AUTOSAR XML (schema 00048)
package /SecurityArchitecture/ComponentTypes
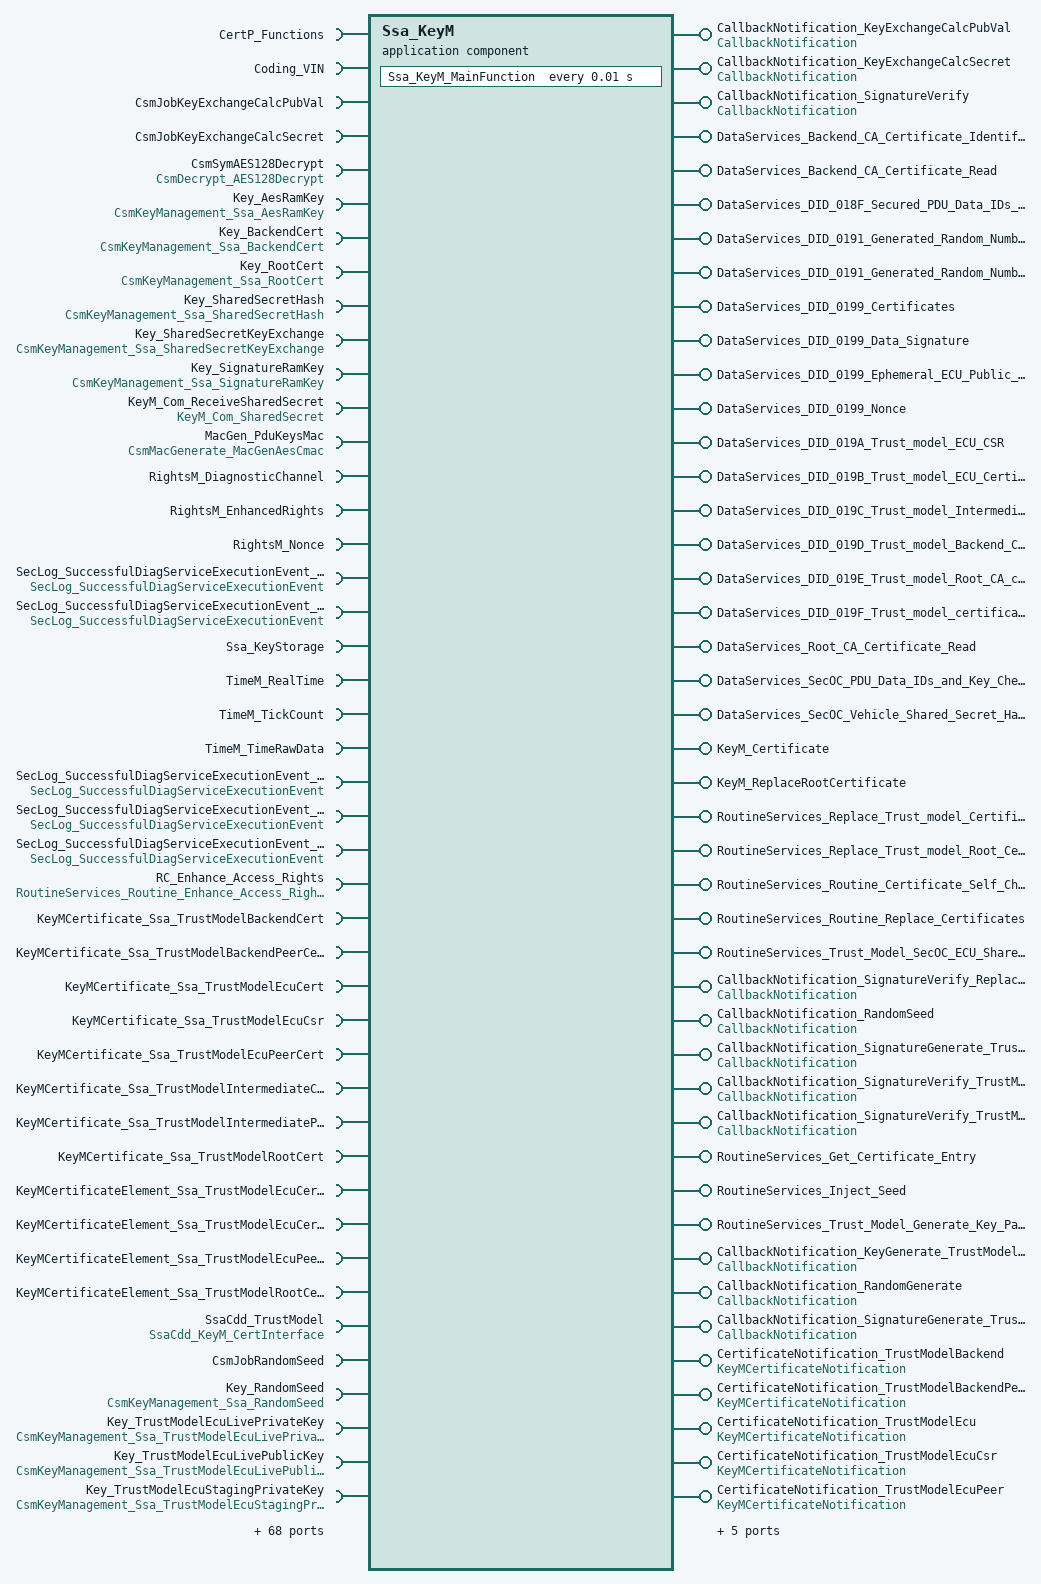
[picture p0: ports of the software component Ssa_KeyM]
  application sw component type Ssa_KeyM
    28 x provide port:
      CallbackNotification_KeyExchangeCalcPubVal: server-com-spec{operation=CallbackNotification, queue-length=1}, provided-interface=CallbackNotification  # Callback notification from the CSM key exchange calculate public value job. Configuration Variant(s): Asynchronous key management job processing.
      CallbackNotification_KeyExchangeCalcSecret: server-com-spec{operation=CallbackNotification, queue-length=1}, provided-interface=CallbackNotification  # Callback notification from the CSM key exchange calculate secret job. Configuration Variant(s): Asynchronous key management job processing.
      CallbackNotification_SignatureVerify: server-com-spec{operation=CallbackNotification, queue-length=1}, provided-interface=CallbackNotification  # Callback notification from the CSM signature verification job used for verifying the signature of passed data with a temporary public key. Configuration Variant(s): Asynchronous job processing.
      DataServices_Backend_CA_Certificate_Identification_Read_Backend_CA_SubjectKeyIdentifier: provided-com-specs=[{operation=ConditionCheckRead, queue-length=1}, {operation=ReadData, queue-length=1}], provided-interface=DataServices_Backend_CA_Certificate_Identification_Read_Backend_CA_SubjectKeyIdentifier  # Reads subject key identifier of backend certificate and pass it to given data parameter. Connect to corresponding Dcm port.
      DataServices_Backend_CA_Certificate_Read: provided-interface=DataServices_Backend_CA_Certificate_Read  # Reads backend certificate and pass it to given data parameter. Connect to corresponding Dcm port.
        provided-com-specs:
          operation=ConditionCheckRead, queue-length=1
          operation=ReadData, queue-length=1
          operation=ReadDataLength, queue-length=1
      DataServices_DID_018F_Secured_PDU_Data_IDs_and_Key_CMACs: provided-interface=DataServices_DID_018F_Secured_PDU_Data_IDs_and_Key_CMACs  # Retrieves all SecOC Data-IDs of the secured PDUs and their corresponding truncated MAC from the ECU.
        provided-com-specs:
          operation=ConditionCheckRead, queue-length=1
          operation=ReadData, queue-length=1
          operation=ReadDataLength, queue-length=1
      DataServices_DID_0191_Generated_Random_Number: provided-com-specs=[{operation=ConditionCheckRead, queue-length=1}, {operation=ReadData, queue-length=1}], provided-interface=DataServices_DID_0191_Generated_Random_Number
      DataServices_DID_0191_Generated_Random_Number_Result: provided-com-specs=[{operation=ConditionCheckRead, queue-length=1}, {operation=ReadData, queue-length=1}], provided-interface=DataServices_DID_0191_Generated_Random_Number_Result
      DataServices_DID_0199_Certificates: provided-interface=DataServices_DID_0199_Certificates  # Reads the certificates and passes it to given data parameter - Unique ECU ID chain. Connect to corresponding Dcm port. Configuration Variant(s): Not in VSM.
        provided-com-specs:
          operation=ConditionCheckRead, queue-length=1
          operation=ReadData, queue-length=1
          operation=ReadDataLength, queue-length=1
      DataServices_DID_0199_Data_Signature: provided-com-specs=[{operation=ConditionCheckRead, queue-length=1}, {operation=ReadData, queue-length=1}], provided-interface=DataServices_DID_0199_Data_Signature  # Reads a signature which was calculated over nonce and ephemeral key and passes it to given data parameter - Unique ECU ID chain. Connect to corresponding Dcm port. Configuration Variant(s): Not in VSM.
      DataServices_DID_0199_Ephemeral_ECU_Public_Key: provided-com-specs=[{operation=ConditionCheckRead, queue-length=1}, {operation=ReadData, queue-length=1}], provided-interface=DataServices_DID_0199_Ephemeral_ECU_Public_Key  # Reads the ephemeral public key and passes it to given data parameter - Unique ECU ID chain. Connect to corresponding Dcm port. Configuration Variant(s): Not in VSM.
      DataServices_DID_0199_Nonce: provided-com-specs=[{operation=ConditionCheckRead, queue-length=1}, {operation=ReadData, queue-length=1}], provided-interface=DataServices_DID_0199_Nonce  # Reads the nonce and passes it to given data parameter - Unique ECU ID chain. Connect to corresponding Dcm port. Configuration Variant(s): Not in VSM.
      DataServices_DID_019A_Trust_model_ECU_CSR: provided-interface=DataServices_DID_019A_Trust_model_ECU_CSR
        provided-com-specs:
          operation=ConditionCheckRead, queue-length=1
          operation=ReadData, queue-length=1
          operation=ReadDataLength, queue-length=1
      DataServices_DID_019B_Trust_model_ECU_Certificate: provided-interface=DataServices_DID_019B_Trust_model_ECU_Certificate
        provided-com-specs:
          operation=ConditionCheckRead, queue-length=1
          operation=ReadData, queue-length=1
          operation=ReadDataLength, queue-length=1
      DataServices_DID_019C_Trust_model_Intermediate_CA_Certificate: provided-interface=DataServices_DID_019C_Trust_model_Intermediate_CA_Certificate
        provided-com-specs:
          operation=ConditionCheckRead, queue-length=1
          operation=ReadData, queue-length=1
          operation=ReadDataLength, queue-length=1
      DataServices_DID_019D_Trust_model_Backend_CA_certificate: provided-interface=DataServices_DID_019D_Trust_model_Backend_CA_certificate
        provided-com-specs:
          operation=ConditionCheckRead, queue-length=1
          operation=ReadData, queue-length=1
          operation=ReadDataLength, queue-length=1
      DataServices_DID_019E_Trust_model_Root_CA_certificate: provided-interface=DataServices_DID_019E_Trust_model_Root_CA_certificate
        provided-com-specs:
          operation=ConditionCheckRead, queue-length=1
          operation=ReadData, queue-length=1
          operation=ReadDataLength, queue-length=1
      DataServices_DID_019F_Trust_model_certificates: provided-interface=DataServices_DID_019F_Trust_model_certificates
        provided-com-specs:
          operation=ConditionCheckRead, queue-length=1
          operation=ReadData, queue-length=1
          operation=ReadDataLength, queue-length=1
      DataServices_Root_CA_Certificate_Read: provided-interface=DataServices_Root_CA_Certificate_Read  # Reads root certificate and passes it to given data parameter. Connect to corresponding Dcm port.
        provided-com-specs:
          operation=ConditionCheckRead, queue-length=1
          operation=ReadData, queue-length=1
          operation=ReadDataLength, queue-length=1
      DataServices_SecOC_PDU_Data_IDs_and_Key_Checksum_Read_Secured_PDU_Data_IDs_and_Key_Checksum: provided-interface=DataServices_SecOC_PDU_Data_IDs_and_Key_Checksum_Read_Secured_PDU_Data_IDs_and_Key_Checksum  # Reads checksum of pdu data identifiers and passes it to given data parameter. Connect to corresponding Dcm port.
        provided-com-specs:
          operation=ConditionCheckRead, queue-length=1
          operation=ReadData, queue-length=1
          operation=ReadDataLength, queue-length=1
      DataServices_SecOC_Vehicle_Shared_Secret_Hash_Read_SecOC_Vehicle_Shared_Secret_Hash: provided-com-specs=[{operation=ConditionCheckRead, queue-length=1}, {operation=ReadData, queue-length=1}], provided-interface=DataServices_SecOC_Vehicle_Shared_Secret_Hash_Read_SecOC_Vehicle_Shared_Secret_Hash  # Reads hash value of shared secret and passes it to given data parameter. Connect to corresponding Dcm port.
      KeyM_Certificate: provided-interface=KeyM_Certificate
        provided-com-specs:
          operation=GetBackendSerialNumber, queue-length=1
          operation=GetBackendSubject, queue-length=1
          operation=VerifyCertWithBackendCert, queue-length=1
          operation=SignData4092ByteWithEcuPrivateKey, queue-length=1
          operation=VerifyCertWithBackendCert, queue-length=1
          operation=SignData1024ByteWithEcuPrivateKey, queue-length=1
          operation=CheckTrustModelChainOfTrust, queue-length=1
      KeyM_ReplaceRootCertificate: nonqueued-sender-com-spec{data-element=isProductive, init-value=constant-reference=Ssa_Init_boolean_False}, provided-interface=KeyM_ReplaceRootCertificate
      RoutineServices_Replace_Trust_model_Certificates: server-com-spec{operation=Start, queue-length=1}, provided-interface=RoutineServices_Replace_Trust_model_Certificates
      RoutineServices_Replace_Trust_model_Root_Certificate: server-com-spec{operation=Start, queue-length=1}, provided-interface=RoutineServices_Replace_Trust_model_Root_Certificate
      RoutineServices_Routine_Certificate_Self_Check: server-com-spec{operation=Start, queue-length=1}, provided-interface=RoutineServices_Routine_Certificate_Self_Check  # Verifies the chain of trust of the stored certificates and their compatibility to the private key.
      RoutineServices_Routine_Replace_Certificates: server-com-spec{operation=Start, queue-length=1}, provided-interface=RoutineServices_Routine_Replace_Certificates  # Replaces the currently stored ECU Certificate, Backend CA Certificate or Root CA Certificate. The Root CA Certificate may only be replaced together with the Backend CA Certificate. The Backend CA Certificate may only be exchanged together with the ECU Certificate. Replacement of Root or Backend certificate needs a corresponding link certificate.
      RoutineServices_Trust_Model_SecOC_ECU_Shared_Secret_Distribution: server-com-spec{operation=Start, queue-length=1}, provided-interface=RoutineServices_Trust_Model_SecOC_ECU_Shared_Secret_Distribution  # Start the distribution of the shared secret - Unique ECU ID chain. Configuration Variant(s): Not in VSM.
    25 x require port:
      CertP_Functions: required-interface=CertP_Functions
        required-com-specs:
          AttributeCertificate_Parse
          Certificate_Compare
          Certificate_Parse
          Certificate_Verify
          Certificate_Verify_Extended
          ParseTime
      Coding_VIN: client-com-spec=Get, required-interface=Coding_VIN
      CsmJobKeyExchangeCalcPubVal: required-com-specs=[CancelJob, KeyExchangeCalcPubVal], required-interface=CsmJobKeyExchangeCalcPubVal  # Calculates a key exchange public value. Connect to a Csm KeyExchangeCalcPubVal job. Configuration Variant(s): Asynchronous key management job processing.
      CsmJobKeyExchangeCalcSecret: required-com-specs=[CancelJob, KeyExchangeCalcSecret], required-interface=CsmJobKeyExchangeCalcSecret  # Calculates a key exchange secret. Connect to a Csm KeyExchangeCalcSecret job. Configuration Variant(s): Asynchronous key management job processing.
      CsmSymAES128Decrypt: client-com-spec=Decrypt, required-interface=CsmDecrypt_AES128Decrypt  # Decrypt data using AES128 with formerly set AesRamKey. Connect to a Csm Decrypt Job which uses the RAM key set through port Key_AesRamKey. Configuration Variant(s): Not in VSM.
      Key_AesRamKey: required-com-specs=[KeyElementGet, KeyElementSet, KeySetValid], required-interface=CsmKeyManagement_Ssa_AesRamKey  # Sets the key used for en- or decrypting the nonce and shared secret. Connect to a Csm Key which is able to store a symmetric key and is used in AES jobs.
      Key_BackendCert: required-com-specs=[KeyElementGet, KeyElementSet, KeySetValid], required-interface=CsmKeyManagement_Ssa_BackendCert  # Key is used to store the Backend certificate. Connect to a Csm Key which is able to store raw certificate data.
      Key_RootCert: required-com-specs=[KeyElementGet, KeyElementSet, KeySetValid], required-interface=CsmKeyManagement_Ssa_RootCert  # Key is used to store the Root certificate. Connect to a Csm Key which is able to store raw certificate data.
      Key_SharedSecretHash: required-com-specs=[KeyElementGet, KeyElementSet, KeySetValid], required-interface=CsmKeyManagement_Ssa_SharedSecretHash  # Key is used to store the proof of the shared secret. Connect to a Csm Key which is able to store a proof of a key.
      Key_SharedSecretKeyExchange: required-com-specs=[KeyElementGet, KeyElementSet, KeyExchangeCalcPubVal, KeyExchangeCalcSecret, KeySetValid], required-interface=CsmKeyManagement_Ssa_SharedSecretKeyExchange  # Key is used to generate a common key between two ecu based on the exchange of its public keys. Connect to a Csm Key which is able to calculate a common secret.
      Key_SignatureRamKey: required-com-specs=[KeyElementGet, KeyElementSet, KeySetValid], required-interface=CsmKeyManagement_Ssa_SignatureRamKey  # Sets the public key of a certificate to verify data signed by this certificate. Connect to a Csm Key which is able to store a public key and is used in job of port CsmSignatureVerify.
      KeyM_Com_ReceiveSharedSecret: nonqueued-receiver-com-spec{data-element=sharedSecret, filter=data-filter-type=ALWAYS, init-value=constant-reference=Ssa_Init_Zero_32Byte}, required-interface=KeyM_Com_SharedSecret  # Configuration Variant(s): Not in VSM.
      MacGen_PduKeysMac: client-com-spec=MacGenerate, required-interface=CsmMacGenerate_MacGenAesCmac  # Generates the MAC from PDU data ID and constant. Connect to a Csm Mac Generate Job which uses the PDU keys MAC key for ReadDataByIdentifier service 0x018F.
      RightsM_DiagnosticChannel: required-com-specs=[GetDiagChanAndAuthStatus, GetDiagnosticUserRole, GetDiagnosticUserRolesBitMask, GetPostProductionStatus], required-interface=RightsM_DiagnosticChannel
      RightsM_EnhancedRights: client-com-spec=VerifySubjectKeyIdentifier, required-interface=RightsM_EnhancedRights
      RightsM_Nonce: required-com-specs=[Destroy, Get], required-interface=RightsM_Nonce
      SecLog_SuccessfulDiagServiceExecutionEvent_EcuSharedSecretDistribution: client-com-spec=SuccessfulDiagServiceExecution, required-interface=SecLog_SuccessfulDiagServiceExecutionEvent  # Configuration Variant(s): Not in VSM.
      SecLog_SuccessfulDiagServiceExecutionEvent_ReplaceCert: client-com-spec=SuccessfulDiagServiceExecution, required-interface=SecLog_SuccessfulDiagServiceExecutionEvent
      Ssa_KeyStorage: client-com-spec=StorePermanently, required-interface=Ssa_KeyStorage
      TimeM_RealTime: required-com-specs=[Compare, Get, Set], required-interface=TimeM_RealTime
      TimeM_TickCount: client-com-spec=Get, required-interface=TimeM_TickCount
      TimeM_TimeRawData: required-com-specs=[Get, Set, ResetLocalTickCount], required-interface=TimeM_TimeRawData
      SecLog_SuccessfulDiagServiceExecutionEvent_ReplaceTrustModelCert: client-com-spec=SuccessfulDiagServiceExecution, required-interface=SecLog_SuccessfulDiagServiceExecutionEvent
      SecLog_SuccessfulDiagServiceExecutionEvent_ReplaceTrustModeRootCert: client-com-spec=SuccessfulDiagServiceExecution, required-interface=SecLog_SuccessfulDiagServiceExecutionEvent
      SecLog_SuccessfulDiagServiceExecutionEvent_TrustModelEcuSharedSecretDistribution: client-com-spec=SuccessfulDiagServiceExecution, required-interface=SecLog_SuccessfulDiagServiceExecutionEvent  # Configuration Variant(s): Not in VSM.
    provide port CallbackNotification_SignatureVerify_ReplacementAuthority: server-com-spec{operation=CallbackNotification, queue-length=1}, provided-interface=CallbackNotification  # Callback notification from the CSM signature verification job used for verifying the signature of passed data with the replacement authority public key. Configuration Variant(s): Asynchronous job processing.
    14 x require port:
      RC_Enhance_Access_Rights: client-com-spec=Start, required-interface=RoutineServices_Routine_Enhance_Access_Rights
      KeyMCertificate_Ssa_TrustModelBackendCert: required-com-specs=[GetStatus, VerifyCertificate], required-interface=KeyMCertificate_Ssa_TrustModelBackendCert
      KeyMCertificate_Ssa_TrustModelBackendPeerCert: required-com-specs=[GetStatus, VerifyCertificate], required-interface=KeyMCertificate_Ssa_TrustModelBackendPeerCert
      KeyMCertificate_Ssa_TrustModelEcuCert: required-com-specs=[GetStatus, VerifyCertificate], required-interface=KeyMCertificate_Ssa_TrustModelEcuCert
      KeyMCertificate_Ssa_TrustModelEcuCsr: required-com-specs=[GetStatus, VerifyCertificate], required-interface=KeyMCertificate_Ssa_TrustModelEcuCsr
      KeyMCertificate_Ssa_TrustModelEcuPeerCert: required-com-specs=[GetStatus, VerifyCertificate], required-interface=KeyMCertificate_Ssa_TrustModelEcuPeerCert
      KeyMCertificate_Ssa_TrustModelIntermediateCert: required-com-specs=[GetStatus, VerifyCertificate], required-interface=KeyMCertificate_Ssa_TrustModelIntermediateCert
      KeyMCertificate_Ssa_TrustModelIntermediatePeerCert: required-com-specs=[GetStatus, VerifyCertificate], required-interface=KeyMCertificate_Ssa_TrustModelIntermediatePeerCert
      KeyMCertificate_Ssa_TrustModelRootCert: required-com-specs=[GetStatus, VerifyCertificate], required-interface=KeyMCertificate_Ssa_TrustModelRootCert
      KeyMCertificateElement_Ssa_TrustModelEcuCert_ext_subKeyId: client-com-spec=CertificateElementGet, required-interface=KeyMCertificateElement_Ssa_TrustModelEcuCert_ext_subKeyId
      KeyMCertificateElement_Ssa_TrustModelEcuCert_ext_uniqueECUID: client-com-spec=CertificateElementGet, required-interface=KeyMCertificateElement_Ssa_TrustModelEcuCert_ext_uniqueECUID
      KeyMCertificateElement_Ssa_TrustModelEcuPeerCert_ext_subKeyId: client-com-spec=CertificateElementGet, required-interface=KeyMCertificateElement_Ssa_TrustModelEcuPeerCert_ext_subKeyId
      KeyMCertificateElement_Ssa_TrustModelRootCert_ext_subKeyId: client-com-spec=CertificateElementGet, required-interface=KeyMCertificateElement_Ssa_TrustModelRootCert_ext_subKeyId
      SsaCdd_TrustModel: required-com-specs=[CsrElementSet, GetCertificate, ServiceCertificate, SetCertificate], required-interface=SsaCdd_KeyM_CertInterface
    7 x provide port:
      CallbackNotification_RandomSeed: server-com-spec{operation=CallbackNotification, queue-length=1}, provided-interface=CallbackNotification  # Callback notification from the CSM random seed job. Configuration Variant(s): Asynchronous key management job processing. Configuration Variant(s): Not in VSM.
      CallbackNotification_SignatureGenerate_TrustModelEcuLive: server-com-spec{operation=CallbackNotification, queue-length=1}, provided-interface=CallbackNotification  # Callback notification from the CSM signature generation job used for generating signatures with the Trust Model ECU live key. Configuration Variant(s): Asynchronous job processing.
      CallbackNotification_SignatureVerify_TrustModelBackend: server-com-spec{operation=CallbackNotification, queue-length=1}, provided-interface=CallbackNotification  # Callback notification from the CSM signature verification job used for verifying the signature of passed data with the public key of the Trust Model Backend CA certificate. Configuration Variant(s): Asynchronous job processing. Configuration Variant(s): Not in VSM.
      CallbackNotification_SignatureVerify_TrustModelTemp: server-com-spec{operation=CallbackNotification, queue-length=1}, provided-interface=CallbackNotification  # Callback notification from the CSM signature verification job used for verifying the signature of passed data with a Trust Model temporary public key. Configuration Variant(s): Asynchronous job processing.
      RoutineServices_Get_Certificate_Entry: server-com-spec{operation=Start, queue-length=1}, provided-interface=RoutineServices_Get_Certificate_Entry  # Routine to read out a specific certificate entry of one of the stored certificates. Connect to DCM.
      RoutineServices_Inject_Seed: server-com-spec{operation=Start, queue-length=1}, provided-interface=RoutineServices_Inject_Seed  # Configuration Variant(s): Not in VSM.
      RoutineServices_Trust_Model_Generate_Key_Pair: server-com-spec{operation=Start, queue-length=1}, provided-interface=RoutineServices_Trust_Model_Generate_Key_Pair
    31 x require port:
      CsmJobRandomSeed: required-com-specs=[CancelJob, RandomSeed], required-interface=CsmJobRandomSeed  # Seeding the random generation algorithm. Connect to a Csm RandomSeed job. Configuration Variant(s): Asynchronous key management job processing. Configuration Variant(s): Not in VSM.
      Key_RandomSeed: required-com-specs=[KeySetValid, RandomSeed], required-interface=CsmKeyManagement_Ssa_RandomSeed  # Key is used to store the seed which shall be used as input for a pseudo random generator. Connect to a Csm Key which is able to store a seed and used by random generator
      Key_TrustModelEcuLivePrivateKey: required-com-specs=[KeyCopy, KeyElementCopy, KeyElementGet, KeyElementSet, KeySetValid], required-interface=CsmKeyManagement_Ssa_TrustModelEcuLivePrivateKey  # Connect to Csm key that is used as private key for the Trust Model ECU certificate.
      Key_TrustModelEcuLivePublicKey: required-com-specs=[KeyCopy, KeyElementCopy, KeyElementGet, KeyElementSet, KeySetValid], required-interface=CsmKeyManagement_Ssa_TrustModelEcuLivePublicKey  # Connect to Csm key that is used as public key for the Trust Model ECU certificate.
      Key_TrustModelEcuStagingPrivateKey: required-com-specs=[KeyCopy, KeyElementCopy, KeyElementGet, KeyElementSet, KeySetValid], required-interface=CsmKeyManagement_Ssa_TrustModelEcuStagingPrivateKey  # Connect to Csm key that is used as private key for the Trust Model ECU CSR certificate.
      Key_TrustModelEcuStagingPublicKey: required-com-specs=[KeyCopy, KeyElementCopy, KeyElementGet, KeyElementSet, KeySetValid], required-interface=CsmKeyManagement_Ssa_TrustModelEcuStagingPublicKey  # Connect to Csm key that is used as public key for the Trust Model ECU CSR certificate.
      Key_TrustModelTempPublicKey: required-com-specs=[KeyCopy, KeyElementCopy, KeyElementGet, KeyElementSet, KeySetValid], required-interface=CsmKeyManagement_Ssa_TrustModelTempPublicKey  # Connect to Csm key that is used as public key for the Trust Model ECU peer certificate.
      KeyMCertificateElement_Ssa_TrustModelBackendCert_ext_authKeyId: client-com-spec=CertificateElementGet, required-interface=KeyMCertificateElement_Ssa_TrustModelBackendCert_ext_authKeyId
      KeyMCertificateElement_Ssa_TrustModelBackendCert_ext_subKeyId: client-com-spec=CertificateElementGet, required-interface=KeyMCertificateElement_Ssa_TrustModelBackendCert_ext_subKeyId
      KeyMCertificateElement_Ssa_TrustModelBackendCert_Issuer: client-com-spec=CertificateElementGet, required-interface=KeyMCertificateElement_Ssa_TrustModelBackendCert_Issuer
      KeyMCertificateElement_Ssa_TrustModelBackendCert_SerialNo: client-com-spec=CertificateElementGet, required-interface=KeyMCertificateElement_Ssa_TrustModelBackendCert_SerialNo
      KeyMCertificateElement_Ssa_TrustModelBackendCert_subject: client-com-spec=CertificateElementGet, required-interface=KeyMCertificateElement_Ssa_TrustModelBackendCert_subject
      KeyMCertificateElement_Ssa_TrustModelBackendCert_SubjectPublicKeyInfoKey: client-com-spec=CertificateElementGet, required-interface=KeyMCertificateElement_Ssa_TrustModelBackendCert_SubjectPublicKeyInfoKey
      KeyMCertificateElement_Ssa_TrustModelEcuCert_ext_authKeyId: client-com-spec=CertificateElementGet, required-interface=KeyMCertificateElement_Ssa_TrustModelEcuCert_ext_authKeyId
      KeyMCertificateElement_Ssa_TrustModelEcuCert_ext_specialEcu: client-com-spec=CertificateElementGet, required-interface=KeyMCertificateElement_Ssa_TrustModelEcuCert_ext_specialEcu
      KeyMCertificateElement_Ssa_TrustModelEcuCert_Issuer: client-com-spec=CertificateElementGet, required-interface=KeyMCertificateElement_Ssa_TrustModelEcuCert_Issuer
      KeyMCertificateElement_Ssa_TrustModelEcuCert_SerialNo: client-com-spec=CertificateElementGet, required-interface=KeyMCertificateElement_Ssa_TrustModelEcuCert_SerialNo
      KeyMCertificateElement_Ssa_TrustModelEcuCert_subject: client-com-spec=CertificateElementGet, required-interface=KeyMCertificateElement_Ssa_TrustModelEcuCert_subject
      KeyMCertificateElement_Ssa_TrustModelEcuCert_SubjectPublicKeyInfoKey: client-com-spec=CertificateElementGet, required-interface=KeyMCertificateElement_Ssa_TrustModelEcuCert_SubjectPublicKeyInfoKey
      KeyMCertificateElement_Ssa_TrustModelIntermediateCert_ext_authKeyId: client-com-spec=CertificateElementGet, required-interface=KeyMCertificateElement_Ssa_TrustModelIntermediateCert_ext_authKeyId
      KeyMCertificateElement_Ssa_TrustModelIntermediateCert_ext_subKeyId: client-com-spec=CertificateElementGet, required-interface=KeyMCertificateElement_Ssa_TrustModelIntermediateCert_ext_subKeyId
      KeyMCertificateElement_Ssa_TrustModelIntermediateCert_Issuer: client-com-spec=CertificateElementGet, required-interface=KeyMCertificateElement_Ssa_TrustModelIntermediateCert_Issuer
      KeyMCertificateElement_Ssa_TrustModelIntermediateCert_SerialNo: client-com-spec=CertificateElementGet, required-interface=KeyMCertificateElement_Ssa_TrustModelIntermediateCert_SerialNo
      KeyMCertificateElement_Ssa_TrustModelIntermediateCert_subject: client-com-spec=CertificateElementGet, required-interface=KeyMCertificateElement_Ssa_TrustModelIntermediateCert_subject
      KeyMCertificateElement_Ssa_TrustModelIntermediateCert_SubjectPublicKeyInfoKey: client-com-spec=CertificateElementGet, required-interface=KeyMCertificateElement_Ssa_TrustModelIntermediateCert_SubjectPublicKeyInfoKey
      KeyMCertificateElement_Ssa_TrustModelRootCert_ext_keyUsage: client-com-spec=CertificateElementGet, required-interface=KeyMCertificateElement_Ssa_TrustModelRootCert_ext_keyUsage
      KeyMCertificateElement_Ssa_TrustModelRootCert_Issuer: client-com-spec=CertificateElementGet, required-interface=KeyMCertificateElement_Ssa_TrustModelRootCert_Issuer
      KeyMCertificateElement_Ssa_TrustModelRootCert_SerialNo: client-com-spec=CertificateElementGet, required-interface=KeyMCertificateElement_Ssa_TrustModelRootCert_SerialNo
      KeyMCertificateElement_Ssa_TrustModelRootCert_subject: client-com-spec=CertificateElementGet, required-interface=KeyMCertificateElement_Ssa_TrustModelRootCert_subject
      KeyMCertificateElement_Ssa_TrustModelRootCert_SubjectPublicKeyInfoKey: client-com-spec=CertificateElementGet, required-interface=KeyMCertificateElement_Ssa_TrustModelRootCert_SubjectPublicKeyInfoKey
      Ssa_KeyProc: required-com-specs=[GenerateKeyPair, PrepareKeyExchange], required-interface=Ssa_KeyProc
    13 x provide port:
      CallbackNotification_KeyGenerate_TrustModelEcuCsr: server-com-spec{operation=CallbackNotification, queue-length=1}, provided-interface=CallbackNotification  # Callback notification from the CSM key generate job. Configuration Variant(s): Asynchronous key management job processing.
      CallbackNotification_RandomGenerate: server-com-spec{operation=CallbackNotification, queue-length=1}, provided-interface=CallbackNotification  # Callback notification from the CSM random generate job. Configuration Variant(s): Asynchronous job processing.
      CallbackNotification_SignatureGenerate_TrustModelEcuCsr: server-com-spec{operation=CallbackNotification, queue-length=1}, provided-interface=CallbackNotification  # Callback notification from the CSM signature generation job used for generating signatures with the Trust Model ECU CSR key. Configuration Variant(s): Asynchronous job processing.
      CertificateNotification_TrustModelBackend: provided-interface=KeyMCertificateNotification
        provided-com-specs:
          operation=CertificateVerifyCallbackNotification, queue-length=1
          operation=ServiceCertificateCallbackNotification, queue-length=1
      CertificateNotification_TrustModelBackendPeer: provided-interface=KeyMCertificateNotification
        provided-com-specs:
          operation=CertificateVerifyCallbackNotification, queue-length=1
          operation=ServiceCertificateCallbackNotification, queue-length=1
      CertificateNotification_TrustModelEcu: provided-interface=KeyMCertificateNotification
        provided-com-specs:
          operation=CertificateVerifyCallbackNotification, queue-length=1
          operation=ServiceCertificateCallbackNotification, queue-length=1
      CertificateNotification_TrustModelEcuCsr: provided-interface=KeyMCertificateNotification
        provided-com-specs:
          operation=CertificateVerifyCallbackNotification, queue-length=1
          operation=ServiceCertificateCallbackNotification, queue-length=1
      CertificateNotification_TrustModelEcuPeer: provided-interface=KeyMCertificateNotification
        provided-com-specs:
          operation=CertificateVerifyCallbackNotification, queue-length=1
          operation=ServiceCertificateCallbackNotification, queue-length=1
      CertificateNotification_TrustModelIntermediate: provided-interface=KeyMCertificateNotification
        provided-com-specs:
          operation=CertificateVerifyCallbackNotification, queue-length=1
          operation=ServiceCertificateCallbackNotification, queue-length=1
      CertificateNotification_TrustModelIntermediatePeer: provided-interface=KeyMCertificateNotification
        provided-com-specs:
          operation=CertificateVerifyCallbackNotification, queue-length=1
          operation=ServiceCertificateCallbackNotification, queue-length=1
      CertificateNotification_TrustModelRoot: provided-interface=KeyMCertificateNotification
        provided-com-specs:
          operation=CertificateVerifyCallbackNotification, queue-length=1
          operation=ServiceCertificateCallbackNotification, queue-length=1
      DataServices_DID_0198_Root_Replacement_Key: provided-com-specs=[{operation=ConditionCheckRead, queue-length=1}, {operation=ReadData, queue-length=1}], provided-interface=DataServices_DID_0198_Root_Replacement_Key  # Reads the Trust Model Root Replacement Key and passes it to the given data parameter. Connect to corresponding Dcm port.
      Ssa_MacKeyGeneration_State: mode-switch-sender-com-spec{mode-group=State, queue-length=1}, provided-interface=Ssa_MacKeyGeneration_State
    42 x require port:
      CsmJobKeyGenerate_TrustModelEcuCsr: required-com-specs=[CancelJob, KeyGenerate], required-interface=CsmJobKeyGenerate  # Generates a new unique ECU key pair. Connect to a Csm KeyGenerate job of the Ed25519 algorithm family. Configuration Variant(s): Asynchronous key management job processing.
      CsmRandomGenerate: client-com-spec=RandomGenerate, required-interface=CsmRandomGenerate_Random  # Generates a random number. Connect to a Csm Random job.
      CsmSymAES128DecryptWithPadding: client-com-spec=Decrypt, required-interface=CsmDecrypt_AES128DecryptWithPadding  # Decrypt data using AES128 with formerly set AesRamKey. Padding bytes needs to be considered. Connect to a Csm Decrypt Job which uses the RAM key set through port Key_AesRamKey. Configuration Variant(s): Not in VSM.
      Key_TrustModelEcuCsrPrivateKey: required-com-specs=[KeyCopy, KeyElementCopy, KeyElementGet, KeyElementSet, KeyGenerate, KeySetValid], required-interface=CsmKeyManagement_Ssa_TrustModelEcuCsrPrivateKey
      Key_TrustModelEcuCsrPublicKey: required-com-specs=[KeyCopy, KeyElementCopy, KeyElementGet, KeyElementSet, KeySetValid], required-interface=CsmKeyManagement_Ssa_TrustModelEcuCsrPublicKey
      Key_TrustModelRootReplacementKey: required-com-specs=[KeyCopy, KeyElementCopy, KeyElementGet, KeyElementSet, KeySetValid], required-interface=CsmKeyManagement_Ssa_SigPubKey_ReplacementAuthority  # Connect to Csm key that is used for signature verification over the New Root CA Certificate package.
      KeyMCertificateElement_Ssa_TrustModelBackendCert_ext_basicConstraints: client-com-spec=CertificateElementGet, required-interface=KeyMCertificateElement_Ssa_TrustModelBackendCert_ext_basicConstraints
      KeyMCertificateElement_Ssa_TrustModelBackendCert_validityNotAfter: client-com-spec=CertificateElementGet, required-interface=KeyMCertificateElement_Ssa_TrustModelBackendCert_validityNotAfter
      KeyMCertificateElement_Ssa_TrustModelBackendCert_Version: client-com-spec=CertificateElementGet, required-interface=KeyMCertificateElement_Ssa_TrustModelBackendCert_Version
      KeyMCertificateElement_Ssa_TrustModelBackendPeerCert_ext_authKeyId: client-com-spec=CertificateElementGet, required-interface=KeyMCertificateElement_Ssa_TrustModelBackendPeerCert_ext_authKeyId
      KeyMCertificateElement_Ssa_TrustModelBackendPeerCert_ext_basicConstraints: client-com-spec=CertificateElementGet, required-interface=KeyMCertificateElement_Ssa_TrustModelBackendPeerCert_ext_basicConstraints
      KeyMCertificateElement_Ssa_TrustModelBackendPeerCert_ext_subKeyId: client-com-spec=CertificateElementGet, required-interface=KeyMCertificateElement_Ssa_TrustModelBackendPeerCert_ext_subKeyId
      KeyMCertificateElement_Ssa_TrustModelBackendPeerCert_SerialNo: client-com-spec=CertificateElementGet, required-interface=KeyMCertificateElement_Ssa_TrustModelBackendPeerCert_SerialNo
      KeyMCertificateElement_Ssa_TrustModelBackendPeerCert_validityNotAfter: client-com-spec=CertificateElementGet, required-interface=KeyMCertificateElement_Ssa_TrustModelBackendPeerCert_validityNotAfter
      KeyMCertificateElement_Ssa_TrustModelBackendPeerCert_Version: client-com-spec=CertificateElementGet, required-interface=KeyMCertificateElement_Ssa_TrustModelBackendPeerCert_Version
      KeyMCertificateElement_Ssa_TrustModelEcuCert_validityNotAfter: client-com-spec=CertificateElementGet, required-interface=KeyMCertificateElement_Ssa_TrustModelEcuCert_validityNotAfter
      KeyMCertificateElement_Ssa_TrustModelEcuCert_Version: client-com-spec=CertificateElementGet, required-interface=KeyMCertificateElement_Ssa_TrustModelEcuCert_Version
      KeyMCertificateElement_Ssa_TrustModelEcuPeerCert_ext_authKeyId: client-com-spec=CertificateElementGet, required-interface=KeyMCertificateElement_Ssa_TrustModelEcuPeerCert_ext_authKeyId
      KeyMCertificateElement_Ssa_TrustModelEcuPeerCert_ext_specialEcu: client-com-spec=CertificateElementGet, required-interface=KeyMCertificateElement_Ssa_TrustModelEcuPeerCert_ext_specialEcu
      KeyMCertificateElement_Ssa_TrustModelEcuPeerCert_SerialNo: client-com-spec=CertificateElementGet, required-interface=KeyMCertificateElement_Ssa_TrustModelEcuPeerCert_SerialNo
      KeyMCertificateElement_Ssa_TrustModelEcuPeerCert_validityNotAfter: client-com-spec=CertificateElementGet, required-interface=KeyMCertificateElement_Ssa_TrustModelEcuPeerCert_validityNotAfter
      KeyMCertificateElement_Ssa_TrustModelEcuPeerCert_Version: client-com-spec=CertificateElementGet, required-interface=KeyMCertificateElement_Ssa_TrustModelEcuPeerCert_Version
      KeyMCertificateElement_Ssa_TrustModelIntermediateCert_ext_basicConstraints: client-com-spec=CertificateElementGet, required-interface=KeyMCertificateElement_Ssa_TrustModelIntermediateCert_ext_basicConstraints
      KeyMCertificateElement_Ssa_TrustModelIntermediateCert_validityNotAfter: client-com-spec=CertificateElementGet, required-interface=KeyMCertificateElement_Ssa_TrustModelIntermediateCert_validityNotAfter
      KeyMCertificateElement_Ssa_TrustModelIntermediateCert_Version: client-com-spec=CertificateElementGet, required-interface=KeyMCertificateElement_Ssa_TrustModelIntermediateCert_Version
      KeyMCertificateElement_Ssa_TrustModelIntermediatePeerCert_ext_authKeyId: client-com-spec=CertificateElementGet, required-interface=KeyMCertificateElement_Ssa_TrustModelIntermediatePeerCert_ext_authKeyId
      KeyMCertificateElement_Ssa_TrustModelIntermediatePeerCert_ext_basicConstraints: client-com-spec=CertificateElementGet, required-interface=KeyMCertificateElement_Ssa_TrustModelIntermediatePeerCert_ext_basicConstraints
      KeyMCertificateElement_Ssa_TrustModelIntermediatePeerCert_ext_subKeyId: client-com-spec=CertificateElementGet, required-interface=KeyMCertificateElement_Ssa_TrustModelIntermediatePeerCert_ext_subKeyId
      KeyMCertificateElement_Ssa_TrustModelIntermediatePeerCert_SerialNo: client-com-spec=CertificateElementGet, required-interface=KeyMCertificateElement_Ssa_TrustModelIntermediatePeerCert_SerialNo
      KeyMCertificateElement_Ssa_TrustModelIntermediatePeerCert_validityNotAfter: client-com-spec=CertificateElementGet, required-interface=KeyMCertificateElement_Ssa_TrustModelIntermediatePeerCert_validityNotAfter
      KeyMCertificateElement_Ssa_TrustModelIntermediatePeerCert_Version: client-com-spec=CertificateElementGet, required-interface=KeyMCertificateElement_Ssa_TrustModelIntermediatePeerCert_Version
      KeyMCertificateElement_Ssa_TrustModelRootCert_ext_basicConstraints: client-com-spec=CertificateElementGet, required-interface=KeyMCertificateElement_Ssa_TrustModelRootCert_ext_basicConstraints
      KeyMCertificateElement_Ssa_TrustModelRootCert_validityNotAfter: client-com-spec=CertificateElementGet, required-interface=KeyMCertificateElement_Ssa_TrustModelRootCert_validityNotAfter
      KeyMCertificateElement_Ssa_TrustModelRootCert_Version: client-com-spec=CertificateElementGet, required-interface=KeyMCertificateElement_Ssa_TrustModelRootCert_Version
      NvMService_KeyM_TrustModelChainOfTrustState: required-com-specs=[GetErrorStatus, ReadBlock, SetRamBlockStatus, WriteBlock], required-interface=NvMService_AC2_SRBS
      SecLog_FailedCertVerificationEvent: client-com-spec=FailedCertificateVerification, required-interface=SecLog_FailedCertVerificationEvent
      SecLog_SuccessfulCertVerificationEvent: client-com-spec=SuccessfulCertificateVerification, required-interface=SecLog_SuccessfulCertVerificationEvent
      SecLog_SuccessfulDiagServiceExecutionEvent_InjectSeed: client-com-spec=SuccessfulDiagServiceExecution, required-interface=SecLog_SuccessfulDiagServiceExecutionEvent  # Configuration Variant(s): Not in VSM.
      SecLog_SuccessfulDiagServiceExecutionEvent_TrustModelGenerateKeyPair: client-com-spec=SuccessfulDiagServiceExecution, required-interface=SecLog_SuccessfulDiagServiceExecutionEvent
      Ssa_VeDocRelevantInfo: client-com-spec=GetData, required-interface=Ssa_VeDocRelevantInfo  # Requests for the VeDoc relevant information, e.g., to be used as common name in the Trust Model CSR.
      SsaCdd_Csm: required-com-specs=[CancelJob, Hash, SignatureGenerate, SignatureVerify], required-interface=SsaCdd_CryptoInterface
      SsaCdd_Keys: required-com-specs=[KeyElementCopy, KeyElementGet, KeyElementSet, KeySetValid], required-interface=SsaCdd_Csm_KeyInterface
    behavior Ssa_KeyM_InternalBehavior: data-type-mapping=SSATypeMappingSet, included-data-type-set=data-type=Ssa_KeyElementType
      exclusive area KeyM_ExclusiveArea
      ar-typed-per-instance-memorys:
        data KeyMTrustModelChainOfTrustState: type=Ssa_TrustModelChainState_Type
      operation invoked event OIT_KeyM_Certificate_GetBackendSerialNumber_KeyM_Certificate_GetBackendSerialNumber: start-on-event=Ssa_KeyM_Certificate_GetBackendSerialNumber, operation=KeyM_Certificate.GetBackendSerialNumber
      operation invoked event OIT_KeyM_KeyM_Certificate_GetBackendSubject_KeyM_Certificate_GetBackendSubject: start-on-event=Ssa_KeyM_Certificate_GetBackendSubject, operation=KeyM_Certificate.GetBackendSubject
      operation invoked event OIT_KeyM_Certificate_VerifyCertWithBackendCert_KeyM_Certificate_VerifyCertWithBackendCert: start-on-event=Ssa_KeyM_Certificate_VerifyCertWithBackendCert, operation=KeyM_Certificate.VerifyCertWithBackendCert
      data received event DRT_KeyM_Com_VehicleSharedSecretNotification_KeyM_ReceiveSharedSecret_sharedSecret: start-on-event=Ssa_KeyM_Com_VehicleSharedSecretNotification, data=KeyM_Com_ReceiveSharedSecret.sharedSecret
      50 x operation invoked event:
        OIT_CallbackNotification_KeyExchangeCalcPubVal_CallbackNotification_CallbackNotification_KeyExchangeCalcPubVal_CallbackND0A1F256: start-on-event=Ssa_KeyM_CsmCallbackNotification_KeyExchangeCalcPubVal, operation=CallbackNotification_KeyExchangeCalcPubVal.CallbackNotification
        OIT_CallbackNotification_KeyExchangeCalcSecret_CallbackNotification_CallbackNotification_KeyExchangeCalcSecret_CallbackN4A055969: start-on-event=Ssa_KeyM_CsmCallbackNotification_KeyExchangeCalcSecret, operation=CallbackNotification_KeyExchangeCalcSecret.CallbackNotification
        OIT_CallbackNotification_SignatureVerify_CallbackNotification_CallbackNotification_SignatureVerify_CallbackNotification: start-on-event=Ssa_KeyM_CsmCallbackNotification_SignatureVerify, operation=CallbackNotification_SignatureVerify.CallbackNotification
        OIT_KeyM_DataServices_Backend_CA_Certificate_Read_ConditionCheckRead_DataServices_Backend_CA_Certificate_Read_ConditionCheckRead: start-on-event=Ssa_KeyM_DataServices_Backend_CA_Certificate_ConditionCheckRead, operation=DataServices_Backend_CA_Certificate_Read.ConditionCheckRead
        OIT_KeyM_DataServices_Backend_CA_Certificate_Identification_Read_Backend_CA_SubjectKeyIdentifier_ConditionCheckRead_Data623BAD1A: start-on-event=Ssa_KeyM_DataServices_Backend_CA_Certificate_Identification_SubjectKeyIdentifier_ConditionCheckRead, operation=DataServices_Backend_CA_Certificate_Identification_Read_Backend_CA_SubjectKeyIdentifier.ConditionCheckRead
        OIT_KeyM_DataServices_Backend_CA_Certificate_Identification_Read_Backend_CA_SubjectKeyIdentifier_ReadData_DataServices_BC7F49EB3: start-on-event=Ssa_KeyM_DataServices_Backend_CA_Certificate_Identification_SubjectKeyIdentifier_ReadData, operation=DataServices_Backend_CA_Certificate_Identification_Read_Backend_CA_SubjectKeyIdentifier.ReadData
        OIT_KeyM_DataServices_Backend_CA_Certificate_Read_ReadData_DataServices_Backend_CA_Certificate_Read_ReadData: start-on-event=Ssa_KeyM_DataServices_Backend_CA_Certificate_ReadData, operation=DataServices_Backend_CA_Certificate_Read.ReadData
        OIT_KeyM_DataServices_Backend_CA_Certificate_Read_ReadDataLength_DataServices_Backend_CA_Certificate_Read_ReadDataLength: start-on-event=Ssa_KeyM_DataServices_Backend_CA_Certificate_ReadDataLength, operation=DataServices_Backend_CA_Certificate_Read.ReadDataLength
        OIT_DataServices_DID_018F_Secured_PDU_Data_IDs_and_Key_CMACs_ConditionCheckRead_DataServices_DID_018F_Secured_PDU_Data_I27C6627C: start-on-event=Ssa_KeyM_DataServices_DID_018F_Secured_PDU_Data_IDs_and_Key_CMACs_ConditionCheckRead, operation=DataServices_DID_018F_Secured_PDU_Data_IDs_and_Key_CMACs.ConditionCheckRead
        OIT_DataServices_DID_018F_Secured_PDU_Data_IDs_and_Key_CMACs_ReadData_DataServices_DID_018F_Secured_PDU_Data_IDs_and_KeyE83D493D: start-on-event=Ssa_KeyM_DataServices_DID_018F_Secured_PDU_Data_IDs_and_Key_CMACs_ReadData, operation=DataServices_DID_018F_Secured_PDU_Data_IDs_and_Key_CMACs.ReadData
        OIT_DataServices_DID_018F_Secured_PDU_Data_IDs_and_Key_CMACs_ReadDataLength_DataServices_DID_018F_Secured_PDU_Data_IDs_a8E9E53EA: start-on-event=Ssa_KeyM_DataServices_DID_018F_Secured_PDU_Data_IDs_and_Key_CMACs_ReadDataLength, operation=DataServices_DID_018F_Secured_PDU_Data_IDs_and_Key_CMACs.ReadDataLength
        OIT_DataServices_DID_0191_Generated_Random_Number_ConditionCheckRead_DataServices_DID_0191_Generated_Random_Number_Condi2EB48B44: start-on-event=Ssa_KeyM_DataServices_DID_0191_Generated_Random_Number_ConditionCheckRead, operation=DataServices_DID_0191_Generated_Random_Number.ConditionCheckRead
        OIT_DataServices_DID_0191_Generated_Random_Number_ReadData_DataServices_DID_0191_Generated_Random_Number_ReadData: start-on-event=Ssa_KeyM_DataServices_DID_0191_Generated_Random_Number_ReadData, operation=DataServices_DID_0191_Generated_Random_Number.ReadData
        OIT_DataServices_DID_0191_Generated_Random_Number_Result_ConditionCheckRead_DataServices_DID_0191_Generated_Random_NumbeC23B856B: start-on-event=Ssa_KeyM_DataServices_DID_0191_Generated_Random_Number_Result_ConditionCheckRead, operation=DataServices_DID_0191_Generated_Random_Number_Result.ConditionCheckRead
        OIT_DataServices_DID_0191_Generated_Random_Number_Result_ReadData_DataServices_DID_0191_Generated_Random_Number_Result_ReadData: start-on-event=Ssa_KeyM_DataServices_DID_0191_Generated_Random_Number_Result_ReadData, operation=DataServices_DID_0191_Generated_Random_Number_Result.ReadData
        OIT_DataServices_DID_0199_Certificates_ConditionCheckRead_DataServices_DID_0199_Certificates_ConditionCheckRead: start-on-event=Ssa_KeyM_DataServices_DID_0199_Certificates_ConditionCheckRead, operation=DataServices_DID_0199_Certificates.ConditionCheckRead
        OIT_DataServices_DID_0199_Certificates_ReadData_DataServices_DID_0199_Certificates_ReadData: start-on-event=Ssa_KeyM_DataServices_DID_0199_Certificates_ReadData, operation=DataServices_DID_0199_Certificates.ReadData
        OIT_DataServices_DID_0199_Certificates_ReadDataLength_DataServices_DID_0199_Certificates_ReadDataLength: start-on-event=Ssa_KeyM_DataServices_DID_0199_Certificates_ReadDataLength, operation=DataServices_DID_0199_Certificates.ReadDataLength
        OIT_DataServices_DID_0199_Data_Signature_ConditionCheckRead_DataServices_DID_0199_Data_Signature_ConditionCheckRead: start-on-event=Ssa_KeyM_DataServices_DID_0199_Data_Signature_ConditionCheckRead, operation=DataServices_DID_0199_Data_Signature.ConditionCheckRead
        OIT_DataServices_DID_0199_Data_Signature_ReadData_DataServices_DID_0199_Data_Signature_ReadData: start-on-event=Ssa_KeyM_DataServices_DID_0199_Data_Signature_ReadData, operation=DataServices_DID_0199_Data_Signature.ReadData
        OIT_DataServices_DID_0199_Ephemeral_ECU_Public_Key_ConditionCheckRead_DataServices_DID_0199_Ephemeral_ECU_Public_Key_ConE39A7F07: start-on-event=Ssa_KeyM_DataServices_DID_0199_Ephemeral_ECU_Public_Key_ConditionCheckRead, operation=DataServices_DID_0199_Ephemeral_ECU_Public_Key.ConditionCheckRead
        OIT_DataServices_DID_0199_Ephemeral_ECU_Public_Key_ReadData_DataServices_DID_0199_Ephemeral_ECU_Public_Key_ReadData: start-on-event=Ssa_KeyM_DataServices_DID_0199_Ephemeral_ECU_Public_Key_ReadData, operation=DataServices_DID_0199_Ephemeral_ECU_Public_Key.ReadData
        OIT_DataServices_DID_0199_Nonce_ConditionCheckRead_DataServices_DID_0199_Nonce_ConditionCheckRead: start-on-event=Ssa_KeyM_DataServices_DID_0199_Nonce_ConditionCheckRead, operation=DataServices_DID_0199_Nonce.ConditionCheckRead
        OIT_DataServices_DID_0199_Nonce_ReadData_DataServices_DID_0199_Nonce_ReadData: start-on-event=Ssa_KeyM_DataServices_DID_0199_Nonce_ReadData, operation=DataServices_DID_0199_Nonce.ReadData
        OIT_DataServices_DID_019A_Trust_model_ECU_CSR_ConditionCheckRead_DataServices_DID_019A_Trust_model_ECU_CSR_ConditionCheckRead: start-on-event=Ssa_KeyM_DataServices_DID_019A_Trust_model_ECU_CSR_ConditionCheckRead, operation=DataServices_DID_019A_Trust_model_ECU_CSR.ConditionCheckRead
        OIT_DataServices_DID_019A_Trust_model_ECU_CSR_ReadData_DataServices_DID_019A_Trust_model_ECU_CSR_ReadData: start-on-event=Ssa_KeyM_DataServices_DID_019A_Trust_model_ECU_CSR_ReadData, operation=DataServices_DID_019A_Trust_model_ECU_CSR.ReadData
        OIT_DataServices_DID_019A_Trust_model_ECU_CSR_ReadDataLength_DataServices_DID_019A_Trust_model_ECU_CSR_ReadDataLength: start-on-event=Ssa_KeyM_DataServices_DID_019A_Trust_model_ECU_CSR_ReadDataLength, operation=DataServices_DID_019A_Trust_model_ECU_CSR.ReadDataLength
        OIT_DataServices_DID_019B_Trust_model_ECU_Certificate_ConditionCheckRead_DataServices_DID_019B_Trust_model_ECU_CertificaDFBBBD9E: start-on-event=Ssa_KeyM_DataServices_DID_019B_Trust_model_ECU_Certificate_ConditionCheckRead, operation=DataServices_DID_019B_Trust_model_ECU_Certificate.ConditionCheckRead
        OIT_DataServices_DID_019B_Trust_model_ECU_Certificate_ReadData_DataServices_DID_019B_Trust_model_ECU_Certificate_ReadData: start-on-event=Ssa_KeyM_DataServices_DID_019B_Trust_model_ECU_Certificate_ReadData, operation=DataServices_DID_019B_Trust_model_ECU_Certificate.ReadData
        OIT_DataServices_DID_019B_Trust_model_ECU_Certificate_ReadDataLength_DataServices_DID_019B_Trust_model_ECU_Certificate_R676F5AD8: start-on-event=Ssa_KeyM_DataServices_DID_019B_Trust_model_ECU_Certificate_ReadDataLength, operation=DataServices_DID_019B_Trust_model_ECU_Certificate.ReadDataLength
        OIT_DataServices_DID_019C_Trust_model_Intermediate_CA_Certificate_ConditionCheckRead_DataServices_DID_019C_Trust_model_IDB6B5447: start-on-event=Ssa_KeyM_DataServices_DID_019C_Trust_model_Intermediate_CA_Certificate_ConditionCheckRead, operation=DataServices_DID_019C_Trust_model_Intermediate_CA_Certificate.ConditionCheckRead
        OIT_DataServices_DID_019C_Trust_model_Intermediate_CA_Certificate_ReadData_DataServices_DID_019C_Trust_model_Intermediat2058FD86: start-on-event=Ssa_KeyM_DataServices_DID_019C_Trust_model_Intermediate_CA_Certificate_ReadData, operation=DataServices_DID_019C_Trust_model_Intermediate_CA_Certificate.ReadData
        OIT_DataServices_DID_019C_Trust_model_Intermediate_CA_Certificate_ReadDataLength_DataServices_DID_019C_Trust_model_Inter10FE0B28: start-on-event=Ssa_KeyM_DataServices_DID_019C_Trust_model_Intermediate_CA_Certificate_ReadDataLength, operation=DataServices_DID_019C_Trust_model_Intermediate_CA_Certificate.ReadDataLength
        OIT_DataServices_DID_019D_Trust_model_Backend_CA_certificate_ConditionCheckRead_DataServices_DID_019D_Trust_model_Backen7B166547: start-on-event=Ssa_KeyM_DataServices_DID_019D_Trust_model_Backend_CA_certificate_ConditionCheckRead, operation=DataServices_DID_019D_Trust_model_Backend_CA_certificate.ConditionCheckRead
        OIT_DataServices_DID_019D_Trust_model_Backend_CA_certificate_ReadData_DataServices_DID_019D_Trust_model_Backend_CA_certi43B2D5AF: start-on-event=Ssa_KeyM_DataServices_DID_019D_Trust_model_Backend_CA_certificate_ReadData, operation=DataServices_DID_019D_Trust_model_Backend_CA_certificate.ReadData
        OIT_DataServices_DID_019D_Trust_model_Backend_CA_certificate_ReadDataLength_DataServices_DID_019D_Trust_model_Backend_CAAB6950B7: start-on-event=Ssa_KeyM_DataServices_DID_019D_Trust_model_Backend_CA_certificate_ReadDataLength, operation=DataServices_DID_019D_Trust_model_Backend_CA_certificate.ReadDataLength
        OIT_DataServices_DID_019E_Trust_model_Root_CA_certificate_ConditionCheckRead_DataServices_DID_019E_Trust_model_Root_CA_cFCCC2278: start-on-event=Ssa_KeyM_DataServices_DID_019E_Trust_model_Root_CA_certificate_ConditionCheckRead, operation=DataServices_DID_019E_Trust_model_Root_CA_certificate.ConditionCheckRead
        OIT_DataServices_DID_019E_Trust_model_Root_CA_certificate_ReadData_DataServices_DID_019E_Trust_model_Root_CA_certificateF1D8D89F: start-on-event=Ssa_KeyM_DataServices_DID_019E_Trust_model_Root_CA_certificate_ReadData, operation=DataServices_DID_019E_Trust_model_Root_CA_certificate.ReadData
        OIT_DataServices_DID_019E_Trust_model_Root_CA_certificate_ReadDataLength_DataServices_DID_019E_Trust_model_Root_CA_certi37DDA313: start-on-event=Ssa_KeyM_DataServices_DID_019E_Trust_model_Root_CA_certificate_ReadDataLength, operation=DataServices_DID_019E_Trust_model_Root_CA_certificate.ReadDataLength
        OIT_DataServices_DID_019F_Trust_model_certificates_ConditionCheckRead_DataServices_DID_019F_Trust_model_certificates_ConC9F0041D: start-on-event=Ssa_KeyM_DataServices_DID_019F_Trust_model_certificates_ConditionCheckRead, operation=DataServices_DID_019F_Trust_model_certificates.ConditionCheckRead
        OIT_DataServices_DID_019F_Trust_model_certificates_ReadData_DataServices_DID_019F_Trust_model_certificates_ReadData: start-on-event=Ssa_KeyM_DataServices_DID_019F_Trust_model_certificates_ReadData, operation=DataServices_DID_019F_Trust_model_certificates.ReadData
        OIT_DataServices_DID_019F_Trust_model_certificates_ReadDataLength_DataServices_DID_019F_Trust_model_certificates_ReadDataLength: start-on-event=Ssa_KeyM_DataServices_DID_019F_Trust_model_certificates_ReadDataLength, operation=DataServices_DID_019F_Trust_model_certificates.ReadDataLength
        OIT_KeyM_DataServices_Root_CA_Certificate_Read_ConditionCheckRead_DataServices_Root_CA_Certificate_Read_ConditionCheckRead: start-on-event=Ssa_KeyM_DataServices_Root_CA_Certificate_Read_ConditionCheckRead, operation=DataServices_Root_CA_Certificate_Read.ConditionCheckRead
        OIT_KeyM_DataServices_Root_CA_Certificate_Read_ReadData_DataServices_Root_CA_Certificate_Read_ReadData: start-on-event=Ssa_KeyM_DataServices_Root_CA_Certificate_Read_ReadData, operation=DataServices_Root_CA_Certificate_Read.ReadData
        OIT_KeyM_DataServices_Root_CA_Certificate_Read_ReadDataLength_DataServices_Root_CA_Certificate_Read_ReadDataLength: start-on-event=Ssa_KeyM_DataServices_Root_CA_Certificate_Read_ReadDataLength, operation=DataServices_Root_CA_Certificate_Read.ReadDataLength
        OIT_DataServices_SecOC_PDU_Data_IDs_and_Key_Checksum_Read_Secured_PDU_Data_IDs_and_Key_Checksum_ConditionCheckRead_DataSFB2915E2: start-on-event=Ssa_KeyM_DataServices_SecOC_PDU_Data_IDs_and_Key_Checksum_ConditionCheckRead, operation=DataServices_SecOC_PDU_Data_IDs_and_Key_Checksum_Read_Secured_PDU_Data_IDs_and_Key_Checksum.ConditionCheckRead
        OIT_DataServices_SecOC_PDU_Data_IDs_and_Key_Checksum_Read_Secured_PDU_Data_IDs_and_Key_Checksum_ReadData_DataServices_Se4D67E2A9: start-on-event=Ssa_KeyM_DataServices_SecOC_PDU_Data_IDs_and_Key_Checksum_ReadData, operation=DataServices_SecOC_PDU_Data_IDs_and_Key_Checksum_Read_Secured_PDU_Data_IDs_and_Key_Checksum.ReadData
        OIT_DataServices_SecOC_PDU_Data_IDs_and_Key_Checksum_Read_Secured_PDU_Data_IDs_and_Key_Checksum_ReadDataLength_DataServi40B113F6: start-on-event=Ssa_KeyM_DataServices_SecOC_PDU_Data_IDs_and_Key_Checksum_ReadDataLength, operation=DataServices_SecOC_PDU_Data_IDs_and_Key_Checksum_Read_Secured_PDU_Data_IDs_and_Key_Checksum.ReadDataLength
        OIT_KeyM_DataServices_SecOC_Vehicle_Shared_Secret_Hash_Read_SecOC_Vehicle_Shared_Secret_Hash_ConditionCheckRead_DataServCCF14E5E: start-on-event=Ssa_KeyM_DataServices_SecOC_Vehicle_Shared_Secret_Hash_ConditionCheckRead, operation=DataServices_SecOC_Vehicle_Shared_Secret_Hash_Read_SecOC_Vehicle_Shared_Secret_Hash.ConditionCheckRead
        OIT_KeyM_DataServices_SecOC_Vehicle_Shared_Secret_Hash_Read_SecOC_Vehicle_Shared_Secret_Hash_ReadData_DataServices_SecOCA8E7B5FF: start-on-event=Ssa_KeyM_DataServices_SecOC_Vehicle_Shared_Secret_Hash_ReadData, operation=DataServices_SecOC_Vehicle_Shared_Secret_Hash_Read_SecOC_Vehicle_Shared_Secret_Hash.ReadData
      init event KeyM_InitEvent: start-on-event=Ssa_KeyM_Init
      timing event TMT_Ssa_KeyM_MainFunction: start-on-event=Ssa_KeyM_MainFunction, period=0.01
      37 x operation invoked event:
        OIT_Ssa_KeyM_RoutineServices_Replace_Certificates_RoutineServices_Routine_Replace_Certificates_Start: start-on-event=Ssa_KeyM_RoutineServices_Replace_Certificates, operation=RoutineServices_Routine_Replace_Certificates.Start
        OIT_RoutineServices_Replace_Trust_model_Certificates_Start_RoutineServices_Replace_Trust_model_Certificates_Start: start-on-event=Ssa_KeyM_RoutineServices_Replace_Trust_model_Certificates, operation=RoutineServices_Replace_Trust_model_Certificates.Start
        OIT_RoutineServices_Replace_Trust_model_Root_Certificate_Start_RoutineServices_Replace_Trust_model_Root_Certificate_Start: start-on-event=Ssa_KeyM_RoutineServices_Replace_Trust_model_Root_Certificate, operation=RoutineServices_Replace_Trust_model_Root_Certificate.Start
        OIT_RoutineServices_Routine_Certificate_Self_Check_Start_RoutineServices_Routine_Certificate_Self_Check_Start: start-on-event=Ssa_KeyM_RoutineServices_Routine_Certificate_Self_Check, operation=RoutineServices_Routine_Certificate_Self_Check.Start
        OIT_RoutineServices_Trust_Model_SecOC_ECU_Shared_Secret_Distribution_Start_RoutineServices_Trust_Model_SecOC_ECU_Shared_36988395: start-on-event=Ssa_KeyM_RoutineServices_Trust_Model_SecOC_ECU_Shared_Secret_Distribution, operation=RoutineServices_Trust_Model_SecOC_ECU_Shared_Secret_Distribution.Start
        OIT_CallbackNotification_RandomGenerateSecret_CallbackNotification_CallbackNotification_RandomGenerateSecret_CallbackNot5A9072CA: start-on-event=Ssa_KeyM_CsmCallbackNotification_RandomGenerate, operation=CallbackNotification_RandomGenerate.CallbackNotification
        OIT_CallbackNotification_SignatureVerify_ReplacementAuthority_CallbackNotification_CallbackNotification_SignatureVerify_73614E2B: start-on-event=Ssa_KeyM_CsmCallbackNotification_SignatureVerify_ReplacementAuthority, operation=CallbackNotification_SignatureVerify_ReplacementAuthority.CallbackNotification
        OIT_Ssa_KeyM_CallbackNotification_KeyGenerate_UniqueEcuKey_CallbackNotification_CallbackNotification_KeyGenerate_UniqueE85276B94: start-on-event=Ssa_KeyM_CsmCallbackNotification_KeyGenerate_TrustModelEcuCsr, operation=CallbackNotification_KeyGenerate_TrustModelEcuCsr.CallbackNotification
        OIT_Ssa_KeyM_CallbackNotification_RandomSeed_CallbackNotification_CallbackNotification_RandomSeed_CallbackNotification: start-on-event=Ssa_KeyM_CsmCallbackNotification_RandomSeed, operation=CallbackNotification_RandomSeed.CallbackNotification
        OIT_CallbackNotification_SignatureVerify_TrustModelBackend_CallbackNotification_CallbackNotification_SignatureVerify_Tru71A027BA: start-on-event=Ssa_KeyM_CsmCallbackNotification_SignatureVerify_TrustModelBackend, operation=CallbackNotification_SignatureVerify_TrustModelBackend.CallbackNotification
        OIT_Ssa_KeyM_RoutineServices_Get_Certificate_Entry_Start_RoutineServices_Get_Certificate_Entry_Start: start-on-event=Ssa_KeyM_RoutineServices_Get_Certificate_Entry_Start, operation=RoutineServices_Get_Certificate_Entry.Start
        OIT_Ssa_KeyM_RoutineServices_Inject_Seed_Start_RoutineServices_Inject_Seed_Start: start-on-event=Ssa_KeyM_RoutineServices_Inject_Seed, operation=RoutineServices_Inject_Seed.Start
        OIT_Ssa_KeyM_RoutineServices_Trust_Model_Generate_Key_Pair_Start_RoutineServices_Trust_Model_Generate_Key_Pair_Start: start-on-event=Ssa_KeyM_RoutineServices_Trust_Model_Generate_Key_Pair, operation=RoutineServices_Trust_Model_Generate_Key_Pair.Start
        OIT_CallbackNotification_SignatureGenerate_TrustModel_CallbackNotification_CallbackNotification_SignatureGenerate_TrustM6E1208F8: start-on-event=Ssa_KeyM_CsmCallbackNotification_SignatureGenerate_TrustModelEcuLive, operation=CallbackNotification_SignatureGenerate_TrustModelEcuLive.CallbackNotification
        OIT_CallbackNotification_SignatureVerify_TrustModel_CallbackNotification_CallbackNotification_SignatureVerify_TrustModelB798FCAA: start-on-event=Ssa_KeyM_CsmCallbackNotification_SignatureVerify_TrustModelTemp, operation=CallbackNotification_SignatureVerify_TrustModelTemp.CallbackNotification
        OIT_KeyM_Certificate_CheckTrustModelChainOfTrust_KeyM_Certificate_CheckTrustModelChainOfTrust: start-on-event=Ssa_KeyM_Certificate_CheckTrustModelChainOfTrust, operation=KeyM_Certificate.CheckTrustModelChainOfTrust
        OIT_KeyM_Certificate_SignData1024ByteWithEcuPrivateKey_KeyM_Certificate_SignData1024ByteWithEcuPrivateKey: start-on-event=Ssa_KeyM_Certificate_SignData1024ByteWithEcuPrivateKey, operation=KeyM_Certificate.SignData1024ByteWithEcuPrivateKey
        OIT_KeyM_Certificate_SignData4092ByteWithEcuPrivateKey_KeyM_Certificate_SignData4092ByteWithEcuPrivateKey: start-on-event=Ssa_KeyM_Certificate_SignData4092ByteWithEcuPrivateKey, operation=KeyM_Certificate.SignData4092ByteWithEcuPrivateKey
        OIT_CallbackNotification_SignatureGenerate_TrustModel_Initial_CallbackNotification_CallbackNotification_SignatureGeneratBD765D2D: start-on-event=Ssa_KeyM_CsmCallbackNotification_SignatureGenerate_TrustModelEcuCsr, operation=CallbackNotification_SignatureGenerate_TrustModelEcuCsr.CallbackNotification
        OIT_DataServices_DID_0198_Root_Replacement_Key_ConditionCheckRead_DataServices_DID_0198_Root_Replacement_Key_ConditionCheckRead: start-on-event=Ssa_KeyM_DataServices_DID_0198_Root_Replacement_Key_ConditionCheckRead, operation=DataServices_DID_0198_Root_Replacement_Key.ConditionCheckRead
        OIT_DataServices_DID_0198_Root_Replacement_Key_ReadData_DataServices_DID_0198_Root_Replacement_Key_ReadData: start-on-event=Ssa_KeyM_DataServices_DID_0198_Root_Replacement_Key_ReadData, operation=DataServices_DID_0198_Root_Replacement_Key.ReadData
        OIT_CertificateNotification_TrustModelBackendCa_CertificateVerifyCallbackNotification_CertificateNotification_TrustModelFDD7CFBA: start-on-event=Ssa_KeyM_KeyMCertificateVerifyCallback_TrustModelBackend, operation=CertificateNotification_TrustModelBackend.CertificateVerifyCallbackNotification
        OIT_CertificateNotification_TrustModelBackendCaPeer_CertificateVerifyCallbackNotification_CertificateNotification_TrustMB16EF89C: start-on-event=Ssa_KeyM_KeyMCertificateVerifyCallback_TrustModelBackendPeer, operation=CertificateNotification_TrustModelBackendPeer.CertificateVerifyCallbackNotification
        OIT_CertificateNotification_TrustModelEcu_CertificateVerifyCallbackNotification_CertificateNotification_TrustModelEcu_CeC72909B7: start-on-event=Ssa_KeyM_KeyMCertificateVerifyCallback_TrustModelEcu, operation=CertificateNotification_TrustModelEcu.CertificateVerifyCallbackNotification
        OIT_CertificateNotification_TrustModelEcuCsr_CertificateVerifyCallbackNotification_CertificateNotification_TrustModelEcuA312EC30: start-on-event=Ssa_KeyM_KeyMCertificateVerifyCallback_TrustModelEcuCsr, operation=CertificateNotification_TrustModelEcuCsr.CertificateVerifyCallbackNotification
        OIT_CertificateNotification_TrustModelEcuPeer_CertificateVerifyCallbackNotification_CertificateNotification_TrustModelEc5F62CAB7: start-on-event=Ssa_KeyM_KeyMCertificateVerifyCallback_TrustModelEcuPeer, operation=CertificateNotification_TrustModelEcuPeer.CertificateVerifyCallbackNotification
        OIT_CertificateNotification_TrustModelIntermediateCa_CertificateVerifyCallbackNotification_CertificateNotification_Trust994774CF: start-on-event=Ssa_KeyM_KeyMCertificateVerifyCallback_TrustModelIntermediate, operation=CertificateNotification_TrustModelIntermediate.CertificateVerifyCallbackNotification
        OIT_CertificateNotification_TrustModelIntermediateCaPeer_CertificateVerifyCallbackNotification_CertificateNotification_T6B37B649: start-on-event=Ssa_KeyM_KeyMCertificateVerifyCallback_TrustModelIntermediatePeer, operation=CertificateNotification_TrustModelIntermediatePeer.CertificateVerifyCallbackNotification
        OIT_CertificateNotification_TrustModelRootCa_CertificateVerifyCallbackNotification_CertificateNotification_TrustModelRoo4D498D67: start-on-event=Ssa_KeyM_KeyMCertificateVerifyCallback_TrustModelRoot, operation=CertificateNotification_TrustModelRoot.CertificateVerifyCallbackNotification
        OIT_CertificateNotification_TrustModelBackendCa_ServiceCertificateCallbackNotification_CertificateNotification_TrustModeF5DE6BA1: start-on-event=Ssa_KeyM_KeyMServiceCertificateCallback_TrustModelBackend, operation=CertificateNotification_TrustModelBackend.ServiceCertificateCallbackNotification
        OIT_CertificateNotification_TrustModelBackendCaPeer_ServiceCertificateCallbackNotification_CertificateNotification_TrustA0BF3411: start-on-event=Ssa_KeyM_KeyMServiceCertificateCallback_TrustModelBackendPeer, operation=CertificateNotification_TrustModelBackendPeer.ServiceCertificateCallbackNotification
        OIT_CertificateNotification_TrustModelEcu_ServiceCertificateCallbackNotification_CertificateNotification_TrustModelEcu_SF95A2917: start-on-event=Ssa_KeyM_KeyMServiceCertificateCallback_TrustModelEcu, operation=CertificateNotification_TrustModelEcu.ServiceCertificateCallbackNotification
        OIT_CertificateNotification_TrustModelEcuCsr_ServiceCertificateCallbackNotification_CertificateNotification_TrustModelEcD51C5486: start-on-event=Ssa_KeyM_KeyMServiceCertificateCallback_TrustModelEcuCsr, operation=CertificateNotification_TrustModelEcuCsr.ServiceCertificateCallbackNotification
        OIT_CertificateNotification_TrustModelEcuPeer_ServiceCertificateCallbackNotification_CertificateNotification_TrustModelE96C8200F: start-on-event=Ssa_KeyM_KeyMServiceCertificateCallback_TrustModelEcuPeer, operation=CertificateNotification_TrustModelEcuPeer.ServiceCertificateCallbackNotification
        OIT_CertificateNotification_TrustModelIntermediateCa_ServiceCertificateCallbackNotification_CertificateNotification_TrusDF6BD314: start-on-event=Ssa_KeyM_KeyMServiceCertificateCallback_TrustModelIntermediate, operation=CertificateNotification_TrustModelIntermediate.ServiceCertificateCallbackNotification
        OIT_CertificateNotification_TrustModelIntermediateCaPeer_ServiceCertificateCallbackNotification_CertificateNotification_A01A1681: start-on-event=Ssa_KeyM_KeyMServiceCertificateCallback_TrustModelIntermediatePeer, operation=CertificateNotification_TrustModelIntermediatePeer.ServiceCertificateCallbackNotification
        OIT_Ssa_KeyM_KeyMServiceCertificateCallback_TrustModelRoot_CertificateNotification_TrustModelRootCa_ServiceCertificateCaE0FC134A: start-on-event=Ssa_KeyM_KeyMServiceCertificateCallback_TrustModelRoot, operation=CertificateNotification_TrustModelRoot.ServiceCertificateCallbackNotification
      port-api-options:
        enable-take-address=false, error-handling=NO-TRANSFORMER-ERROR-HANDLING, indirect-api=false, port=CertP_Functions
        enable-take-address=false, error-handling=NO-TRANSFORMER-ERROR-HANDLING, indirect-api=false, port=Coding_VIN
        enable-take-address=false, error-handling=NO-TRANSFORMER-ERROR-HANDLING, indirect-api=false, port=CsmSymAES128Decrypt
        enable-take-address=false, error-handling=NO-TRANSFORMER-ERROR-HANDLING, indirect-api=false, port=DataServices_Backend_CA_Certificate_Identification_Read_Backend_CA_SubjectKeyIdentifier
        enable-take-address=false, error-handling=NO-TRANSFORMER-ERROR-HANDLING, indirect-api=false, port=DataServices_Backend_CA_Certificate_Read
        enable-take-address=false, error-handling=NO-TRANSFORMER-ERROR-HANDLING, indirect-api=false, port=DataServices_Root_CA_Certificate_Read
        enable-take-address=false, error-handling=NO-TRANSFORMER-ERROR-HANDLING, indirect-api=false, port=DataServices_SecOC_PDU_Data_IDs_and_Key_Checksum_Read_Secured_PDU_Data_IDs_and_Key_Checksum
        enable-take-address=false, error-handling=NO-TRANSFORMER-ERROR-HANDLING, indirect-api=false, port=DataServices_SecOC_Vehicle_Shared_Secret_Hash_Read_SecOC_Vehicle_Shared_Secret_Hash
        enable-take-address=false, error-handling=NO-TRANSFORMER-ERROR-HANDLING, indirect-api=false, port=Key_AesRamKey
        enable-take-address=false, error-handling=NO-TRANSFORMER-ERROR-HANDLING, indirect-api=false, port=Key_BackendCert
        enable-take-address=false, error-handling=NO-TRANSFORMER-ERROR-HANDLING, indirect-api=false, port=Key_RootCert
        enable-take-address=false, error-handling=NO-TRANSFORMER-ERROR-HANDLING, indirect-api=false, port=Key_SharedSecretHash
        enable-take-address=false, error-handling=NO-TRANSFORMER-ERROR-HANDLING, indirect-api=false, port=Key_SharedSecretKeyExchange
        enable-take-address=false, error-handling=NO-TRANSFORMER-ERROR-HANDLING, indirect-api=false, port=Key_SignatureRamKey
        enable-take-address=false, error-handling=NO-TRANSFORMER-ERROR-HANDLING, indirect-api=false, port=KeyM_Certificate
        enable-take-address=false, error-handling=NO-TRANSFORMER-ERROR-HANDLING, indirect-api=false, port=KeyM_Com_ReceiveSharedSecret
        enable-take-address=false, error-handling=NO-TRANSFORMER-ERROR-HANDLING, indirect-api=false, port=KeyM_ReplaceRootCertificate
        enable-take-address=false, error-handling=NO-TRANSFORMER-ERROR-HANDLING, indirect-api=false, port=RightsM_DiagnosticChannel
        enable-take-address=false, error-handling=NO-TRANSFORMER-ERROR-HANDLING, indirect-api=false, port=RightsM_EnhancedRights
        enable-take-address=false, error-handling=NO-TRANSFORMER-ERROR-HANDLING, indirect-api=false, port=RightsM_Nonce
        enable-take-address=false, error-handling=NO-TRANSFORMER-ERROR-HANDLING, indirect-api=false, port=SecLog_SuccessfulDiagServiceExecutionEvent_EcuSharedSecretDistribution
        enable-take-address=false, error-handling=NO-TRANSFORMER-ERROR-HANDLING, indirect-api=false, port=SecLog_SuccessfulDiagServiceExecutionEvent_ReplaceCert
        enable-take-address=false, error-handling=NO-TRANSFORMER-ERROR-HANDLING, indirect-api=false, port=Ssa_KeyStorage
        enable-take-address=false, error-handling=NO-TRANSFORMER-ERROR-HANDLING, indirect-api=false, port=TimeM_RealTime
        enable-take-address=false, error-handling=NO-TRANSFORMER-ERROR-HANDLING, indirect-api=false, port=TimeM_TickCount
        enable-take-address=false, error-handling=NO-TRANSFORMER-ERROR-HANDLING, indirect-api=false, port=TimeM_TimeRawData
        enable-take-address=true, error-handling=NO-TRANSFORMER-ERROR-HANDLING, indirect-api=false, port=KeyMCertificateElement_Ssa_TrustModelBackendCert_ext_authKeyId
        enable-take-address=true, error-handling=NO-TRANSFORMER-ERROR-HANDLING, indirect-api=false, port=KeyMCertificateElement_Ssa_TrustModelBackendCert_ext_subKeyId
        enable-take-address=true, error-handling=NO-TRANSFORMER-ERROR-HANDLING, indirect-api=false, port=KeyMCertificateElement_Ssa_TrustModelBackendCert_Issuer
        enable-take-address=true, error-handling=NO-TRANSFORMER-ERROR-HANDLING, indirect-api=false, port=KeyMCertificateElement_Ssa_TrustModelBackendCert_SerialNo
        enable-take-address=true, error-handling=NO-TRANSFORMER-ERROR-HANDLING, indirect-api=false, port=KeyMCertificateElement_Ssa_TrustModelBackendCert_subject
        enable-take-address=true, error-handling=NO-TRANSFORMER-ERROR-HANDLING, indirect-api=false, port=KeyMCertificateElement_Ssa_TrustModelBackendCert_SubjectPublicKeyInfoKey
        enable-take-address=true, error-handling=NO-TRANSFORMER-ERROR-HANDLING, indirect-api=false, port=KeyMCertificateElement_Ssa_TrustModelEcuCert_ext_authKeyId
        enable-take-address=true, error-handling=NO-TRANSFORMER-ERROR-HANDLING, indirect-api=false, port=KeyMCertificateElement_Ssa_TrustModelEcuCert_ext_specialEcu
        enable-take-address=true, error-handling=NO-TRANSFORMER-ERROR-HANDLING, indirect-api=false, port=KeyMCertificateElement_Ssa_TrustModelEcuCert_ext_subKeyId
        enable-take-address=true, error-handling=NO-TRANSFORMER-ERROR-HANDLING, indirect-api=false, port=KeyMCertificateElement_Ssa_TrustModelEcuCert_ext_uniqueECUID
        enable-take-address=true, error-handling=NO-TRANSFORMER-ERROR-HANDLING, indirect-api=false, port=KeyMCertificateElement_Ssa_TrustModelEcuCert_Issuer
        enable-take-address=true, error-handling=NO-TRANSFORMER-ERROR-HANDLING, indirect-api=false, port=KeyMCertificateElement_Ssa_TrustModelEcuCert_SerialNo
        enable-take-address=true, error-handling=NO-TRANSFORMER-ERROR-HANDLING, indirect-api=false, port=KeyMCertificateElement_Ssa_TrustModelEcuCert_subject
        enable-take-address=true, error-handling=NO-TRANSFORMER-ERROR-HANDLING, indirect-api=false, port=KeyMCertificateElement_Ssa_TrustModelEcuCert_SubjectPublicKeyInfoKey
        enable-take-address=true, error-handling=NO-TRANSFORMER-ERROR-HANDLING, indirect-api=false, port=KeyMCertificateElement_Ssa_TrustModelEcuPeerCert_ext_subKeyId
        enable-take-address=true, error-handling=NO-TRANSFORMER-ERROR-HANDLING, indirect-api=false, port=KeyMCertificateElement_Ssa_TrustModelIntermediateCert_ext_authKeyId
        enable-take-address=true, error-handling=NO-TRANSFORMER-ERROR-HANDLING, indirect-api=false, port=KeyMCertificateElement_Ssa_TrustModelIntermediateCert_ext_subKeyId
        enable-take-address=true, error-handling=NO-TRANSFORMER-ERROR-HANDLING, indirect-api=false, port=KeyMCertificateElement_Ssa_TrustModelIntermediateCert_Issuer
        enable-take-address=true, error-handling=NO-TRANSFORMER-ERROR-HANDLING, indirect-api=false, port=KeyMCertificateElement_Ssa_TrustModelIntermediateCert_SerialNo
        enable-take-address=true, error-handling=NO-TRANSFORMER-ERROR-HANDLING, indirect-api=false, port=KeyMCertificateElement_Ssa_TrustModelIntermediateCert_subject
        enable-take-address=true, error-handling=NO-TRANSFORMER-ERROR-HANDLING, indirect-api=false, port=KeyMCertificateElement_Ssa_TrustModelIntermediateCert_SubjectPublicKeyInfoKey
        enable-take-address=true, error-handling=NO-TRANSFORMER-ERROR-HANDLING, indirect-api=false, port=KeyMCertificateElement_Ssa_TrustModelRootCert_ext_keyUsage
        enable-take-address=true, error-handling=NO-TRANSFORMER-ERROR-HANDLING, indirect-api=false, port=KeyMCertificateElement_Ssa_TrustModelRootCert_ext_subKeyId
        enable-take-address=true, error-handling=NO-TRANSFORMER-ERROR-HANDLING, indirect-api=false, port=KeyMCertificateElement_Ssa_TrustModelRootCert_Issuer
        enable-take-address=true, error-handling=NO-TRANSFORMER-ERROR-HANDLING, indirect-api=false, port=KeyMCertificateElement_Ssa_TrustModelRootCert_SerialNo
        enable-take-address=true, error-handling=NO-TRANSFORMER-ERROR-HANDLING, indirect-api=false, port=KeyMCertificateElement_Ssa_TrustModelRootCert_subject
        enable-take-address=true, error-handling=NO-TRANSFORMER-ERROR-HANDLING, indirect-api=false, port=KeyMCertificateElement_Ssa_TrustModelRootCert_SubjectPublicKeyInfoKey
        enable-take-address=false, error-handling=NO-TRANSFORMER-ERROR-HANDLING, indirect-api=false, port=CsmRandomGenerate
        enable-take-address=false, error-handling=NO-TRANSFORMER-ERROR-HANDLING, indirect-api=false, port=CsmSymAES128DecryptWithPadding
        enable-take-address=true, error-handling=NO-TRANSFORMER-ERROR-HANDLING, indirect-api=false, port=KeyMCertificateElement_Ssa_TrustModelBackendCert_ext_basicConstraints
        enable-take-address=true, error-handling=NO-TRANSFORMER-ERROR-HANDLING, indirect-api=false, port=KeyMCertificateElement_Ssa_TrustModelBackendCert_validityNotAfter
        enable-take-address=true, error-handling=NO-TRANSFORMER-ERROR-HANDLING, indirect-api=false, port=KeyMCertificateElement_Ssa_TrustModelBackendCert_Version
        enable-take-address=true, error-handling=NO-TRANSFORMER-ERROR-HANDLING, indirect-api=false, port=KeyMCertificateElement_Ssa_TrustModelBackendPeerCert_ext_authKeyId
        enable-take-address=true, error-handling=NO-TRANSFORMER-ERROR-HANDLING, indirect-api=false, port=KeyMCertificateElement_Ssa_TrustModelBackendPeerCert_ext_basicConstraints
        enable-take-address=true, error-handling=NO-TRANSFORMER-ERROR-HANDLING, indirect-api=false, port=KeyMCertificateElement_Ssa_TrustModelBackendPeerCert_ext_subKeyId
        enable-take-address=true, error-handling=NO-TRANSFORMER-ERROR-HANDLING, indirect-api=false, port=KeyMCertificateElement_Ssa_TrustModelBackendPeerCert_validityNotAfter
        enable-take-address=true, error-handling=NO-TRANSFORMER-ERROR-HANDLING, indirect-api=false, port=KeyMCertificateElement_Ssa_TrustModelBackendPeerCert_Version
        enable-take-address=true, error-handling=NO-TRANSFORMER-ERROR-HANDLING, indirect-api=false, port=KeyMCertificateElement_Ssa_TrustModelEcuCert_validityNotAfter
        enable-take-address=true, error-handling=NO-TRANSFORMER-ERROR-HANDLING, indirect-api=false, port=KeyMCertificateElement_Ssa_TrustModelEcuCert_Version
        enable-take-address=true, error-handling=NO-TRANSFORMER-ERROR-HANDLING, indirect-api=false, port=KeyMCertificateElement_Ssa_TrustModelEcuPeerCert_ext_authKeyId
        enable-take-address=true, error-handling=NO-TRANSFORMER-ERROR-HANDLING, indirect-api=false, port=KeyMCertificateElement_Ssa_TrustModelEcuPeerCert_ext_specialEcu
        enable-take-address=true, error-handling=NO-TRANSFORMER-ERROR-HANDLING, indirect-api=false, port=KeyMCertificateElement_Ssa_TrustModelEcuPeerCert_validityNotAfter
        enable-take-address=true, error-handling=NO-TRANSFORMER-ERROR-HANDLING, indirect-api=false, port=KeyMCertificateElement_Ssa_TrustModelEcuPeerCert_Version
        enable-take-address=true, error-handling=NO-TRANSFORMER-ERROR-HANDLING, indirect-api=false, port=KeyMCertificateElement_Ssa_TrustModelIntermediateCert_ext_basicConstraints
        enable-take-address=true, error-handling=NO-TRANSFORMER-ERROR-HANDLING, indirect-api=false, port=KeyMCertificateElement_Ssa_TrustModelIntermediateCert_validityNotAfter
        enable-take-address=true, error-handling=NO-TRANSFORMER-ERROR-HANDLING, indirect-api=false, port=KeyMCertificateElement_Ssa_TrustModelIntermediateCert_Version
        enable-take-address=true, error-handling=NO-TRANSFORMER-ERROR-HANDLING, indirect-api=false, port=KeyMCertificateElement_Ssa_TrustModelIntermediatePeerCert_ext_authKeyId
        enable-take-address=true, error-handling=NO-TRANSFORMER-ERROR-HANDLING, indirect-api=false, port=KeyMCertificateElement_Ssa_TrustModelIntermediatePeerCert_ext_basicConstraints
        enable-take-address=true, error-handling=NO-TRANSFORMER-ERROR-HANDLING, indirect-api=false, port=KeyMCertificateElement_Ssa_TrustModelIntermediatePeerCert_ext_subKeyId
        enable-take-address=true, error-handling=NO-TRANSFORMER-ERROR-HANDLING, indirect-api=false, port=KeyMCertificateElement_Ssa_TrustModelIntermediatePeerCert_validityNotAfter
        enable-take-address=true, error-handling=NO-TRANSFORMER-ERROR-HANDLING, indirect-api=false, port=KeyMCertificateElement_Ssa_TrustModelIntermediatePeerCert_Version
        enable-take-address=true, error-handling=NO-TRANSFORMER-ERROR-HANDLING, indirect-api=false, port=KeyMCertificateElement_Ssa_TrustModelRootCert_ext_basicConstraints
        enable-take-address=true, error-handling=NO-TRANSFORMER-ERROR-HANDLING, indirect-api=false, port=KeyMCertificateElement_Ssa_TrustModelRootCert_validityNotAfter
        enable-take-address=true, error-handling=NO-TRANSFORMER-ERROR-HANDLING, indirect-api=false, port=KeyMCertificateElement_Ssa_TrustModelRootCert_Version
        enable-take-address=false, error-handling=NO-TRANSFORMER-ERROR-HANDLING, indirect-api=false, port=SsaCdd_Keys
      93 x runnable:
        Ssa_KeyM_Certificate_GetBackendSerialNumber
          sync call SC_CertP_Functions_CertP_Certificate_Parse: operation=CertP_Functions.Certificate_Parse
          sync call SC_Key_BackendCert_KeyElementGet: operation=Key_BackendCert.KeyElementGet
        Ssa_KeyM_Certificate_GetBackendSubject
          sync call SC_CertP_Functions_CertP_Certificate_Parse: operation=CertP_Functions.Certificate_Parse
          sync call SC_Key_BackendCert_KeyElementGet: operation=Key_BackendCert.KeyElementGet
        Ssa_KeyM_Certificate_VerifyCertWithBackendCert
          4 x sync call:
            SC_CertP_Functions_Certificate_Verify_Extended: operation=CertP_Functions.Certificate_Verify_Extended
            SC_CertP_Functions_CertP_Certificate_Parse: operation=CertP_Functions.Certificate_Parse
            SC_CertP_Functions_CertP_Certificate_Verify: operation=CertP_Functions.Certificate_Verify
            SC_Key_BackendCert_KeyElementGet: operation=Key_BackendCert.KeyElementGet
        Ssa_KeyM_Com_VehicleSharedSecretNotification: can-enter-exclusive-area=KeyM_ExclusiveArea  # Is called by Com when the broadcast message containing the car-specific secret signal is received. Configuration Variant(s): Not in VSM.
          data-receive-point-by-arguments:
            access REC_KeyM_Com_ReceiveSharedSecret_sharedSecret: accessed-variable=KeyM_Com_ReceiveSharedSecret.sharedSecret
          sync call SC_RightsM_DiagnosticChannel_GetDiagnosticUserRole: operation=RightsM_DiagnosticChannel.GetDiagnosticUserRolesBitMask
        Ssa_KeyM_CsmCallbackNotification_KeyExchangeCalcPubVal  # Configuration Variant(s): Asynchronous key management job processing.
        Ssa_KeyM_CsmCallbackNotification_KeyExchangeCalcSecret  # Configuration Variant(s): Asynchronous key management job processing.
        Ssa_KeyM_CsmCallbackNotification_SignatureVerify  # Configuration Variant(s): Asynchronous job processing.
        Ssa_KeyM_DataServices_Backend_CA_Certificate_ConditionCheckRead
        Ssa_KeyM_DataServices_Backend_CA_Certificate_Identification_SubjectKeyIdentifier_ConditionCheckRead
        Ssa_KeyM_DataServices_Backend_CA_Certificate_Identification_SubjectKeyIdentifier_ReadData
          sync call SC_CertP_Functions_Certificate_Parse: operation=CertP_Functions.Certificate_Parse
          sync call SC_Key_BackendCert_KeyElementGet: operation=Key_BackendCert.KeyElementGet
        Ssa_KeyM_DataServices_Backend_CA_Certificate_ReadData
          sync call SC_CertP_Functions_Certificate_Parse: operation=CertP_Functions.Certificate_Parse
          sync call SC_Key_BackendCert_KeyElementGet: operation=Key_BackendCert.KeyElementGet
        Ssa_KeyM_DataServices_Backend_CA_Certificate_ReadDataLength
          sync call SC_CertP_Functions_Certificate_Parse: operation=CertP_Functions.Certificate_Parse
          sync call SC_Key_BackendCert_KeyElementGet: operation=Key_BackendCert.KeyElementGet
        Ssa_KeyM_DataServices_DID_018F_Secured_PDU_Data_IDs_and_Key_CMACs_ConditionCheckRead
        Ssa_KeyM_DataServices_DID_018F_Secured_PDU_Data_IDs_and_Key_CMACs_ReadData
          sync call SC_MacGen_PduKeysMac_MacGenerate: operation=MacGen_PduKeysMac.MacGenerate
          sync call SC_SsaCdd_SymKeys_KeyElementCopy: operation=SsaCdd_Keys.KeyElementCopy
          sync call SC_SsaCdd_SymKeys_KeySetValid: operation=SsaCdd_Keys.KeySetValid
        Ssa_KeyM_DataServices_DID_018F_Secured_PDU_Data_IDs_and_Key_CMACs_ReadDataLength
        Ssa_KeyM_DataServices_DID_0191_Generated_Random_Number_ConditionCheckRead
          sync call SC_CsmRandomGenerateSecret_RandomGenerate: operation=CsmRandomGenerate.RandomGenerate
        Ssa_KeyM_DataServices_DID_0191_Generated_Random_Number_ReadData
        Ssa_KeyM_DataServices_DID_0191_Generated_Random_Number_Result_ConditionCheckRead
        Ssa_KeyM_DataServices_DID_0191_Generated_Random_Number_Result_ReadData
        Ssa_KeyM_DataServices_DID_0199_Certificates_ConditionCheckRead  # Configuration Variant(s): Not in VSM.
          6 x sync call:
            SC_RightsM_DiagnosticChannel_GetDiagnosticUserRole: operation=RightsM_DiagnosticChannel.GetDiagnosticUserRole
            SC_RightsM_EnhancedRights_VerifySubjectKeyIdentifier: operation=RightsM_EnhancedRights.VerifySubjectKeyIdentifier
            SC_KeyMCertificate_Ssa_TrustModelBackendCert_GetStatus: operation=KeyMCertificate_Ssa_TrustModelBackendCert.GetStatus
            SC_KeyMCertificate_Ssa_TrustModelEcuCert_GetStatus: operation=KeyMCertificate_Ssa_TrustModelEcuCert.GetStatus
            SC_KeyMCertificate_Ssa_TrustModelIntermediateCert_GetStatus: operation=KeyMCertificate_Ssa_TrustModelIntermediateCert.GetStatus
            SC_KeyMCertificateElement_Ssa_TrustModelEcuCert_ext_subKeyId_CertificateElementGet: operation=KeyMCertificateElement_Ssa_TrustModelEcuCert_ext_subKeyId.CertificateElementGet
        Ssa_KeyM_DataServices_DID_0199_Certificates_ReadData  # Configuration Variant(s): Not in VSM.
          sync call SC_SsaCdd_TrustModel_GetCertificate: operation=SsaCdd_TrustModel.GetCertificate
        Ssa_KeyM_DataServices_DID_0199_Certificates_ReadDataLength  # Configuration Variant(s): Not in VSM.
          sync call SC_SsaCdd_TrustModel_GetCertificate: operation=SsaCdd_TrustModel.GetCertificate
        Ssa_KeyM_DataServices_DID_0199_Data_Signature_ConditionCheckRead  # Configuration Variant(s): Not in VSM.
        Ssa_KeyM_DataServices_DID_0199_Data_Signature_ReadData  # Configuration Variant(s): Not in VSM.
          sync call SC_Key_SharedSecretKeyExchange_KeyElementGet: operation=Key_SharedSecretKeyExchange.KeyElementGet
          sync call SC_RightsM_Nonce_Get: operation=RightsM_Nonce.Get
          sync call SC_SsaCdd_Csm_SignatureGenerate: operation=SsaCdd_Csm.SignatureGenerate
        Ssa_KeyM_DataServices_DID_0199_Ephemeral_ECU_Public_Key_ConditionCheckRead  # Configuration Variant(s): Not in VSM.
        Ssa_KeyM_DataServices_DID_0199_Ephemeral_ECU_Public_Key_ReadData  # Configuration Variant(s): Not in VSM.
          5 x sync call:
            SC_CsmJobKeyExchangeCalcPubVal_KeyExchangeCalcPubVal: operation=CsmJobKeyExchangeCalcPubVal.KeyExchangeCalcPubVal
            SC_Key_SharedSecretKeyExchange_KeyElementSet: operation=Key_SharedSecretKeyExchange.KeyElementSet
            SC_Key_SharedSecretKeyExchange_KeyExchangeCalcPubVal: operation=Key_SharedSecretKeyExchange.KeyExchangeCalcPubVal
            SC_Key_SharedSecretKeyExchange_KeySetValid: operation=Key_SharedSecretKeyExchange.KeySetValid
            SC_Ssa_KeyProc_PrepareKeyExchange: operation=Ssa_KeyProc.PrepareKeyExchange
        Ssa_KeyM_DataServices_DID_0199_Nonce_ConditionCheckRead  # Configuration Variant(s): Not in VSM.
          sync call SC_RightsM_Nonce_Get: operation=RightsM_Nonce.Get
        Ssa_KeyM_DataServices_DID_0199_Nonce_ReadData  # Configuration Variant(s): Not in VSM.
          sync call SC_RightsM_Nonce_Get: operation=RightsM_Nonce.Get
        Ssa_KeyM_DataServices_DID_019A_Trust_model_ECU_CSR_ConditionCheckRead
          12 x sync call:
            SC_SsaCdd_TrustModel_CsrElementSet: operation=SsaCdd_TrustModel.CsrElementSet
            SC_SsaCdd_TrustModel_ServiceCertificate: operation=SsaCdd_TrustModel.ServiceCertificate
            SC_Key_TrustModelEcuCsrPrivateKey_KeySetValid_1: operation=Key_TrustModelEcuCsrPrivateKey.KeySetValid
            SC_Key_TrustModelEcuCsrPublicKey_KeyElementGet_1: operation=Key_TrustModelEcuCsrPublicKey.KeyElementGet
            SC_Key_TrustModelEcuCsrPublicKey_KeySetValid_1: operation=Key_TrustModelEcuCsrPublicKey.KeySetValid
            SC_Key_TrustModelEcuStagingPrivateKey_KeyElementCopy: operation=Key_TrustModelEcuStagingPrivateKey.KeyElementCopy
            SC_Key_TrustModelEcuStagingPublicKey_KeyElementCopy: operation=Key_TrustModelEcuStagingPublicKey.KeyElementCopy
            SC_Key_TrustModelTempPublicKey_KeyElementSet: operation=Key_TrustModelTempPublicKey.KeyElementSet
            SC_Key_TrustModelTempPublicKey_KeySetValid: operation=Key_TrustModelTempPublicKey.KeySetValid
            SC_Ssa_VedocRelevantInfo_GetData: operation=Ssa_VeDocRelevantInfo.GetData
            SC_SsaCdd_Csm_SignatureGenerate: operation=SsaCdd_Csm.SignatureGenerate
            SC_SsaCdd_Csm_SignatureVerify: operation=SsaCdd_Csm.SignatureVerify
        Ssa_KeyM_DataServices_DID_019A_Trust_model_ECU_CSR_ReadData
        Ssa_KeyM_DataServices_DID_019A_Trust_model_ECU_CSR_ReadDataLength
        Ssa_KeyM_DataServices_DID_019B_Trust_model_ECU_Certificate_ConditionCheckRead
          sync call SC_KeyMCertificate_Ssa_TrustModelEcuCert_GetStatus: operation=KeyMCertificate_Ssa_TrustModelEcuCert.GetStatus
        Ssa_KeyM_DataServices_DID_019B_Trust_model_ECU_Certificate_ReadData
          sync call SC_SsaCdd_TrustModel_GetCertificate: operation=SsaCdd_TrustModel.GetCertificate
        Ssa_KeyM_DataServices_DID_019B_Trust_model_ECU_Certificate_ReadDataLength
          sync call SC_SsaCdd_TrustModel_GetCertificate: operation=SsaCdd_TrustModel.GetCertificate
        Ssa_KeyM_DataServices_DID_019C_Trust_model_Intermediate_CA_Certificate_ConditionCheckRead
          sync call SC_KeyMCertificate_Ssa_TrustModelIntermediateCert_GetStatus: operation=KeyMCertificate_Ssa_TrustModelIntermediateCert.GetStatus
        Ssa_KeyM_DataServices_DID_019C_Trust_model_Intermediate_CA_Certificate_ReadData
          sync call SC_SsaCdd_TrustModel_GetCertificate: operation=SsaCdd_TrustModel.GetCertificate
        Ssa_KeyM_DataServices_DID_019C_Trust_model_Intermediate_CA_Certificate_ReadDataLength
          sync call SC_SsaCdd_TrustModel_GetCertificate: operation=SsaCdd_TrustModel.GetCertificate
        Ssa_KeyM_DataServices_DID_019D_Trust_model_Backend_CA_certificate_ConditionCheckRead
          sync call SC_KeyMCertificate_Ssa_TrustModelBackendCert_GetStatus: operation=KeyMCertificate_Ssa_TrustModelBackendCert.GetStatus
        Ssa_KeyM_DataServices_DID_019D_Trust_model_Backend_CA_certificate_ReadData
          sync call SC_SsaCdd_TrustModel_GetCertificate: operation=SsaCdd_TrustModel.GetCertificate
        Ssa_KeyM_DataServices_DID_019D_Trust_model_Backend_CA_certificate_ReadDataLength
          sync call SC_SsaCdd_TrustModel_GetCertificate: operation=SsaCdd_TrustModel.GetCertificate
        Ssa_KeyM_DataServices_DID_019E_Trust_model_Root_CA_certificate_ConditionCheckRead
          sync call SC_KeyMCertificate_Ssa_TrustModelRootCert_GetStatus: operation=KeyMCertificate_Ssa_TrustModelRootCert.GetStatus
        Ssa_KeyM_DataServices_DID_019E_Trust_model_Root_CA_certificate_ReadData
          sync call SC_SsaCdd_TrustModel_GetCertificate: operation=SsaCdd_TrustModel.GetCertificate
        Ssa_KeyM_DataServices_DID_019E_Trust_model_Root_CA_certificate_ReadDataLength
          sync call SC_SsaCdd_TrustModel_GetCertificate: operation=SsaCdd_TrustModel.GetCertificate
        Ssa_KeyM_DataServices_DID_019F_Trust_model_certificates_ConditionCheckRead
          4 x sync call:
            SC_KeyMCertificate_Ssa_TrustModelBackendCert_GetStatus: operation=KeyMCertificate_Ssa_TrustModelBackendCert.GetStatus
            SC_KeyMCertificate_Ssa_TrustModelEcuCert_GetStatus: operation=KeyMCertificate_Ssa_TrustModelEcuCert.GetStatus
            SC_KeyMCertificate_Ssa_TrustModelIntermediateCert_GetStatus: operation=KeyMCertificate_Ssa_TrustModelIntermediateCert.GetStatus
            SC_KeyMCertificate_Ssa_TrustModelRootCert_GetStatus: operation=KeyMCertificate_Ssa_TrustModelRootCert.GetStatus
        Ssa_KeyM_DataServices_DID_019F_Trust_model_certificates_ReadData
          sync call SC_SsaCdd_TrustModel_GetCertificate: operation=SsaCdd_TrustModel.GetCertificate
        Ssa_KeyM_DataServices_DID_019F_Trust_model_certificates_ReadDataLength
          sync call SC_SsaCdd_TrustModel_GetCertificate: operation=SsaCdd_TrustModel.GetCertificate
        Ssa_KeyM_DataServices_Root_CA_Certificate_Read_ConditionCheckRead
        Ssa_KeyM_DataServices_Root_CA_Certificate_Read_ReadData
          sync call SC_CertP_Functions_Certificate_Parse: operation=CertP_Functions.Certificate_Parse
          sync call SC_Key_RootCert_KeyElementGet: operation=Key_RootCert.KeyElementGet
        Ssa_KeyM_DataServices_Root_CA_Certificate_Read_ReadDataLength
          sync call SC_CertP_Functions_Certificate_Parse: operation=CertP_Functions.Certificate_Parse
          sync call SC_Key_RootCert_KeyElementGet: operation=Key_RootCert.KeyElementGet
        Ssa_KeyM_DataServices_SecOC_PDU_Data_IDs_and_Key_Checksum_ConditionCheckRead
        Ssa_KeyM_DataServices_SecOC_PDU_Data_IDs_and_Key_Checksum_ReadData
          sync call SC_SsaCdd_SymKeys_KeyElementGet: operation=SsaCdd_Keys.KeyElementGet
        Ssa_KeyM_DataServices_SecOC_PDU_Data_IDs_and_Key_Checksum_ReadDataLength
        Ssa_KeyM_DataServices_SecOC_Vehicle_Shared_Secret_Hash_ConditionCheckRead
        Ssa_KeyM_DataServices_SecOC_Vehicle_Shared_Secret_Hash_ReadData
          sync call SC_Key_SharedSecretHash_KeyElementGet: operation=Key_SharedSecretHash.KeyElementGet
        Ssa_KeyM_Init
          5 x sync call:
            SC_Key_SharedSecretHash_KeyElementGet: operation=Key_SharedSecretHash.KeyElementGet
            SC_Key_TrustModelEcuCsrPrivateKey_KeySetValid_1: operation=Key_TrustModelEcuCsrPrivateKey.KeySetValid
            SC_Key_TrustModelEcuCsrPublicKey_KeySetValid_1: operation=Key_TrustModelEcuCsrPublicKey.KeySetValid
            SC_Key_TrustModelEcuStagingPrivateKey_KeyElementCopy: operation=Key_TrustModelEcuStagingPrivateKey.KeyElementCopy
            SC_Key_TrustModelEcuStagingPublicKey_KeyElementCopy: operation=Key_TrustModelEcuStagingPublicKey.KeyElementCopy
        Ssa_KeyM_MainFunction
          mode switch point SWITCH_Ssa_MacKeyGeneration_State_State: mode-group=Ssa_MacKeyGeneration_State.State
          8 x sync call:
            SC_Coding_VIN_Get: operation=Coding_VIN.Get
            SC_Key_SharedSecretHash_KeyElementSet: operation=Key_SharedSecretHash.KeyElementSet
            SC_Key_SharedSecretHash_KeySetValid: operation=Key_SharedSecretHash.KeySetValid
            SC_Ssa_KeyStorage_StorePermanently: operation=Ssa_KeyStorage.StorePermanently
            SC_SsaCdd_SymKeys_KeyElementSet: operation=SsaCdd_Keys.KeyElementSet
            SC_SsaCdd_SymKeys_KeySetValid: operation=SsaCdd_Keys.KeySetValid
            SC_TimeM_TimeRawData_ResetLocalTickCount: operation=TimeM_TimeRawData.ResetLocalTickCount
            SC_SsaCdd_Csm_Hash: operation=SsaCdd_Csm.Hash
        Ssa_KeyM_RoutineServices_Replace_Certificates
          data-send-points:
            access SEND_KeyM_ReplaceRootCertificate_isProductive: accessed-variable=KeyM_ReplaceRootCertificate.isProductive
          13 x sync call:
            SC_CertP_Functions_Certificate_Compare: operation=CertP_Functions.Certificate_Compare
            SC_CertP_Functions_Certificate_Parse: operation=CertP_Functions.Certificate_Parse
            SC_CertP_Functions_Certificate_Verify: operation=CertP_Functions.Certificate_Verify
            SC_Key_BackendCert_KeyElementGet: operation=Key_BackendCert.KeyElementGet
            SC_Key_RootCert_KeyElementGet: operation=Key_RootCert.KeyElementGet
            SC_Key_SignatureRamKey_KeyElementSet: operation=Key_SignatureRamKey.KeyElementSet
            SC_Key_SignatureRamKey_KeySetValid: operation=Key_SignatureRamKey.KeySetValid
            SC_SecLog_SuccessfulDiagServiceExecutionEvent_ReplaceCert_SuccessfulDiagServiceExecution: operation=SecLog_SuccessfulDiagServiceExecutionEvent_ReplaceCert.SuccessfulDiagServiceExecution
            SC_Ssa_KeyStorage_StorePermanently: operation=Ssa_KeyStorage.StorePermanently
            SC_SsaCdd_Csm_SignatureGenerate: operation=SsaCdd_Csm.SignatureGenerate
            SC_SsaCdd_Csm_SignatureVerify: operation=SsaCdd_Csm.SignatureVerify
            SC_SsaCdd_Keys_KeyElementSet: operation=SsaCdd_Keys.KeyElementSet
            SC_SsaCdd_Keys_KeySetValid: operation=SsaCdd_Keys.KeySetValid
        Ssa_KeyM_RoutineServices_Replace_Trust_model_Certificates
          65 x sync call:
            SC_SecLog_SuccessfulDiagServiceExecutionEvent_ReplaceTrustModelCert_SuccessfulDiagServiceExecution: operation=SecLog_SuccessfulDiagServiceExecutionEvent_ReplaceTrustModelCert.SuccessfulDiagServiceExecution
            SC_Ssa_KeyStorage_StorePermanently: operation=Ssa_KeyStorage.StorePermanently
            SC_KeyMCertificate_Ssa_TrustModelBackendCert_GetStatus: operation=KeyMCertificate_Ssa_TrustModelBackendCert.GetStatus
            SC_KeyMCertificate_Ssa_TrustModelEcuCert_GetStatus: operation=KeyMCertificate_Ssa_TrustModelEcuCert.GetStatus
            SC_KeyMCertificate_Ssa_TrustModelEcuCert_VerifyCertificate: operation=KeyMCertificate_Ssa_TrustModelEcuCert.VerifyCertificate
            SC_KeyMCertificate_Ssa_TrustModelIntermediateCert_GetStatus: operation=KeyMCertificate_Ssa_TrustModelIntermediateCert.GetStatus
            SC_KeyMCertificate_Ssa_TrustModelRootCert_GetStatus: operation=KeyMCertificate_Ssa_TrustModelRootCert.GetStatus
            SC_KeyMCertificateElement_Ssa_TrustModelEcuCert_ext_uniqueECUID_CertificateElementGet: operation=KeyMCertificateElement_Ssa_TrustModelEcuCert_ext_uniqueECUID.CertificateElementGet
            SC_SsaCdd_TrustModel_GetCertificate: operation=SsaCdd_TrustModel.GetCertificate
            SC_SsaCdd_TrustModel_ServiceCertificate: operation=SsaCdd_TrustModel.ServiceCertificate
            SC_SsaCdd_TrustModel_SetCertificate: operation=SsaCdd_TrustModel.SetCertificate
            SC_Key_TrustModelEcuLivePublicKey_KeyElementGet: operation=Key_TrustModelEcuLivePublicKey.KeyElementGet
            SC_Key_TrustModelEcuStagingPrivateKey_KeyElementCopy: operation=Key_TrustModelEcuStagingPrivateKey.KeyElementCopy
            SC_Key_TrustModelTempPublicKey_KeyElementSet: operation=Key_TrustModelTempPublicKey.KeyElementSet
            SC_Key_TrustModelTempPublicKey_KeySetValid: operation=Key_TrustModelTempPublicKey.KeySetValid
            SC_CertP_Functions_ParseTime: operation=CertP_Functions.ParseTime
            SC_Key_TrustModelEcuCsrPrivateKey_KeyElementCopy_1: operation=Key_TrustModelEcuCsrPrivateKey.KeyElementCopy
            SC_Key_TrustModelEcuCsrPublicKey_KeyElementCopy_1: operation=Key_TrustModelEcuCsrPublicKey.KeyElementCopy
            SC_Key_TrustModelEcuLivePrivateKey_KeySetValid: operation=Key_TrustModelEcuLivePrivateKey.KeySetValid
            SC_Key_TrustModelEcuStagingPrivateKey_KeySetValid: operation=Key_TrustModelEcuStagingPrivateKey.KeySetValid
            SC_Key_TrustModelEcuStagingPublicKey_KeySetValid: operation=Key_TrustModelEcuStagingPublicKey.KeySetValid
            SC_KeyMCertificateElement_Ssa_TrustModelBackendCert_ext_authKeyId_CertificateElementGet: operation=KeyMCertificateElement_Ssa_TrustModelBackendCert_ext_authKeyId.CertificateElementGet
            SC_KeyMCertificateElement_Ssa_TrustModelBackendCert_ext_basicConstraints_CertificateElementGet: operation=KeyMCertificateElement_Ssa_TrustModelBackendCert_ext_basicConstraints.CertificateElementGet
            SC_KeyMCertificateElement_Ssa_TrustModelBackendCert_ext_subKeyId_CertificateElementGet: operation=KeyMCertificateElement_Ssa_TrustModelBackendCert_ext_subKeyId.CertificateElementGet
            SC_KeyMCertificateElement_Ssa_TrustModelBackendCert_Issuer_CertificateElementGet: operation=KeyMCertificateElement_Ssa_TrustModelBackendCert_Issuer.CertificateElementGet
            SC_KeyMCertificateElement_Ssa_TrustModelBackendCert_SerialNo_CertificateElementGet: operation=KeyMCertificateElement_Ssa_TrustModelBackendCert_SerialNo.CertificateElementGet
            SC_KeyMCertificateElement_Ssa_TrustModelBackendCert_subject_CertificateElementGet: operation=KeyMCertificateElement_Ssa_TrustModelBackendCert_subject.CertificateElementGet
            SC_KeyMCertificateElement_Ssa_TrustModelBackendCert_SubjectPublicKeyInfoKey_CertificateElementGet: operation=KeyMCertificateElement_Ssa_TrustModelBackendCert_SubjectPublicKeyInfoKey.CertificateElementGet
            SC_KeyMCertificateElement_Ssa_TrustModelBackendCert_validityNotAfter_CertificateElementGet: operation=KeyMCertificateElement_Ssa_TrustModelBackendCert_validityNotAfter.CertificateElementGet
            SC_KeyMCertificateElement_Ssa_TrustModelBackendCert_Version_CertificateElementGet: operation=KeyMCertificateElement_Ssa_TrustModelBackendCert_Version.CertificateElementGet
            SC_KeyMCertificateElement_Ssa_TrustModelEcuCert_ext_authKeyId_CertificateElementGet: operation=KeyMCertificateElement_Ssa_TrustModelEcuCert_ext_authKeyId.CertificateElementGet
            SC_KeyMCertificateElement_Ssa_TrustModelEcuCert_ext_specialEcu_CertificateElementGet: operation=KeyMCertificateElement_Ssa_TrustModelEcuCert_ext_specialEcu.CertificateElementGet
            SC_KeyMCertificateElement_Ssa_TrustModelEcuCert_ext_subKeyId_CertificateElementGet: operation=KeyMCertificateElement_Ssa_TrustModelEcuCert_ext_subKeyId.CertificateElementGet
            SC_KeyMCertificateElement_Ssa_TrustModelEcuCert_Issuer_CertificateElementGet: operation=KeyMCertificateElement_Ssa_TrustModelEcuCert_Issuer.CertificateElementGet
            SC_KeyMCertificateElement_Ssa_TrustModelEcuCert_SerialNo_CertificateElementGet: operation=KeyMCertificateElement_Ssa_TrustModelEcuCert_SerialNo.CertificateElementGet
            SC_KeyMCertificateElement_Ssa_TrustModelEcuCert_subject_CertificateElementGet: operation=KeyMCertificateElement_Ssa_TrustModelEcuCert_subject.CertificateElementGet
            SC_KeyMCertificateElement_Ssa_TrustModelEcuCert_SubjectPublicKeyInfoKey_CertificateElementGet: operation=KeyMCertificateElement_Ssa_TrustModelEcuCert_SubjectPublicKeyInfoKey.CertificateElementGet
            SC_KeyMCertificateElement_Ssa_TrustModelEcuCert_validityNotAfter_CertificateElementGet: operation=KeyMCertificateElement_Ssa_TrustModelEcuCert_validityNotAfter.CertificateElementGet
            SC_KeyMCertificateElement_Ssa_TrustModelEcuCert_Version_CertificateElementGet: operation=KeyMCertificateElement_Ssa_TrustModelEcuCert_Version.CertificateElementGet
            SC_KeyMCertificateElement_Ssa_TrustModelIntermediateCert_ext_authKeyId_CertificateElementGet: operation=KeyMCertificateElement_Ssa_TrustModelIntermediateCert_ext_authKeyId.CertificateElementGet
            SC_KeyMCertificateElement_Ssa_TrustModelIntermediateCert_ext_basicConstraints_CertificateElementGet: operation=KeyMCertificateElement_Ssa_TrustModelIntermediateCert_ext_basicConstraints.CertificateElementGet
            SC_KeyMCertificateElement_Ssa_TrustModelIntermediateCert_ext_subKeyId_CertificateElementGet: operation=KeyMCertificateElement_Ssa_TrustModelIntermediateCert_ext_subKeyId.CertificateElementGet
            SC_KeyMCertificateElement_Ssa_TrustModelIntermediateCert_Issuer_CertificateElementGet: operation=KeyMCertificateElement_Ssa_TrustModelIntermediateCert_Issuer.CertificateElementGet
            SC_KeyMCertificateElement_Ssa_TrustModelIntermediateCert_SerialNo_CertificateElementGet: operation=KeyMCertificateElement_Ssa_TrustModelIntermediateCert_SerialNo.CertificateElementGet
            SC_KeyMCertificateElement_Ssa_TrustModelIntermediateCert_subject_CertificateElementGet: operation=KeyMCertificateElement_Ssa_TrustModelIntermediateCert_subject.CertificateElementGet
            SC_KeyMCertificateElement_Ssa_TrustModelIntermediateCert_SubjectPublicKeyInfoKey_CertificateElementGet: operation=KeyMCertificateElement_Ssa_TrustModelIntermediateCert_SubjectPublicKeyInfoKey.CertificateElementGet
            SC_KeyMCertificateElement_Ssa_TrustModelIntermediateCert_validityNotAfter_CertificateElementGet: operation=KeyMCertificateElement_Ssa_TrustModelIntermediateCert_validityNotAfter.CertificateElementGet
            SC_KeyMCertificateElement_Ssa_TrustModelIntermediateCert_Version_CertificateElementGet: operation=KeyMCertificateElement_Ssa_TrustModelIntermediateCert_Version.CertificateElementGet
            SC_KeyMCertificateElement_Ssa_TrustModelRootCert_ext_basicConstraints_CertificateElementGet: operation=KeyMCertificateElement_Ssa_TrustModelRootCert_ext_basicConstraints.CertificateElementGet
            SC_KeyMCertificateElement_Ssa_TrustModelRootCert_ext_keyUsage_CertificateElementGet: operation=KeyMCertificateElement_Ssa_TrustModelRootCert_ext_keyUsage.CertificateElementGet
            SC_KeyMCertificateElement_Ssa_TrustModelRootCert_ext_subKeyId_CertificateElementGet: operation=KeyMCertificateElement_Ssa_TrustModelRootCert_ext_subKeyId.CertificateElementGet
            SC_KeyMCertificateElement_Ssa_TrustModelRootCert_Issuer_CertificateElementGet: operation=KeyMCertificateElement_Ssa_TrustModelRootCert_Issuer.CertificateElementGet
            SC_KeyMCertificateElement_Ssa_TrustModelRootCert_SerialNo_CertificateElementGet: operation=KeyMCertificateElement_Ssa_TrustModelRootCert_SerialNo.CertificateElementGet
            SC_KeyMCertificateElement_Ssa_TrustModelRootCert_subject_CertificateElementGet: operation=KeyMCertificateElement_Ssa_TrustModelRootCert_subject.CertificateElementGet
            SC_KeyMCertificateElement_Ssa_TrustModelRootCert_SubjectPublicKeyInfoKey_CertificateElementGet: operation=KeyMCertificateElement_Ssa_TrustModelRootCert_SubjectPublicKeyInfoKey.CertificateElementGet
            SC_KeyMCertificateElement_Ssa_TrustModelRootCert_validityNotAfter_CertificateElementGet: operation=KeyMCertificateElement_Ssa_TrustModelRootCert_validityNotAfter.CertificateElementGet
            SC_KeyMCertificateElement_Ssa_TrustModelRootCert_Version_CertificateElementGet: operation=KeyMCertificateElement_Ssa_TrustModelRootCert_Version.CertificateElementGet
            SC_NvMService_KeyM_TrsutModelChainOfTrustState_GetErrorStatus: operation=NvMService_KeyM_TrustModelChainOfTrustState.GetErrorStatus
            SC_NvMService_KeyM_TrsutModelChainOfTrustState_WriteBlock: operation=NvMService_KeyM_TrustModelChainOfTrustState.WriteBlock
            SC_SecLog_FailedCertVerificationEvent_FailedCertificateVerification: operation=SecLog_FailedCertVerificationEvent.FailedCertificateVerification
            SC_SecLog_SuccessfulCertVerificationEvent_SuccessfulCertificateVerification: operation=SecLog_SuccessfulCertVerificationEvent.SuccessfulCertificateVerification
            SC_SsaCdd_Csm_SignatureGenerate: operation=SsaCdd_Csm.SignatureGenerate
            SC_SsaCdd_Csm_SignatureVerify: operation=SsaCdd_Csm.SignatureVerify
            SC_TimeM_RealTime_Compare: operation=TimeM_RealTime.Compare
            SC_TimeM_RealTime_Get: operation=TimeM_RealTime.Get
        Ssa_KeyM_RoutineServices_Replace_Trust_model_Root_Certificate
          27 x sync call:
            SC_SecLog_SuccessfulDiagServiceExecutionEvent_ReplaceTrustModeRootCert_SuccessfulDiagServiceExecution: operation=SecLog_SuccessfulDiagServiceExecutionEvent_ReplaceTrustModeRootCert.SuccessfulDiagServiceExecution
            SC_Ssa_KeyStorage_StorePermanently: operation=Ssa_KeyStorage.StorePermanently
            SC_CertP_Functions_Certificate_Parse: operation=CertP_Functions.Certificate_Parse
            SC_Key_BackendCert_KeyElementGet: operation=Key_BackendCert.KeyElementGet
            SC_Key_RootCert_KeyElementGet: operation=Key_RootCert.KeyElementGet
            SC_Key_SignatureRamKey_KeyElementSet: operation=Key_SignatureRamKey.KeyElementSet
            SC_Key_SignatureRamKey_KeySetValid: operation=Key_SignatureRamKey.KeySetValid
            SC_RC_Enhance_Access_Rights_Start: operation=RC_Enhance_Access_Rights.Start
            SC_KeyMCertificate_Ssa_TrustModelRootCert_GetStatus: operation=KeyMCertificate_Ssa_TrustModelRootCert.GetStatus
            SC_KeyMCertificateElement_Ssa_TrustModelRootCert_ext_subKeyId_CertificateElementGet: operation=KeyMCertificateElement_Ssa_TrustModelRootCert_ext_subKeyId.CertificateElementGet
            SC_SsaCdd_TrustModel_ServiceCertificate: operation=SsaCdd_TrustModel.ServiceCertificate
            SC_CertP_Functions_ParseTime: operation=CertP_Functions.ParseTime
            SC_KeyMCertificateElement_Ssa_TrustModelRootCert_ext_basicConstraints_CertificateElementGet: operation=KeyMCertificateElement_Ssa_TrustModelRootCert_ext_basicConstraints.CertificateElementGet
            SC_KeyMCertificateElement_Ssa_TrustModelRootCert_ext_keyUsage_CertificateElementGet: operation=KeyMCertificateElement_Ssa_TrustModelRootCert_ext_keyUsage.CertificateElementGet
            SC_KeyMCertificateElement_Ssa_TrustModelRootCert_Issuer_CertificateElementGet: operation=KeyMCertificateElement_Ssa_TrustModelRootCert_Issuer.CertificateElementGet
            SC_KeyMCertificateElement_Ssa_TrustModelRootCert_SerialNo_CertificateElementGet: operation=KeyMCertificateElement_Ssa_TrustModelRootCert_SerialNo.CertificateElementGet
            SC_KeyMCertificateElement_Ssa_TrustModelRootCert_subject_CertificateElementGet: operation=KeyMCertificateElement_Ssa_TrustModelRootCert_subject.CertificateElementGet
            SC_KeyMCertificateElement_Ssa_TrustModelRootCert_SubjectPublicKeyInfoKey_CertificateElementGet: operation=KeyMCertificateElement_Ssa_TrustModelRootCert_SubjectPublicKeyInfoKey.CertificateElementGet
            SC_KeyMCertificateElement_Ssa_TrustModelRootCert_validityNotAfter_CertificateElementGet: operation=KeyMCertificateElement_Ssa_TrustModelRootCert_validityNotAfter.CertificateElementGet
            SC_KeyMCertificateElement_Ssa_TrustModelRootCert_Version_CertificateElementGet: operation=KeyMCertificateElement_Ssa_TrustModelRootCert_Version.CertificateElementGet
            SC_NvMService_KeyM_TrsutModelChainOfTrustState_GetErrorStatus: operation=NvMService_KeyM_TrustModelChainOfTrustState.GetErrorStatus
            SC_NvMService_KeyM_TrsutModelChainOfTrustState_WriteBlock: operation=NvMService_KeyM_TrustModelChainOfTrustState.WriteBlock
            SC_SecLog_FailedCertVerificationEvent_FailedCertificateVerification: operation=SecLog_FailedCertVerificationEvent.FailedCertificateVerification
            SC_SecLog_SuccessfulCertVerificationEvent_SuccessfulCertificateVerification: operation=SecLog_SuccessfulCertVerificationEvent.SuccessfulCertificateVerification
            SC_SsaCdd_Csm_SignatureVerify: operation=SsaCdd_Csm.SignatureVerify
            SC_TimeM_RealTime_Compare: operation=TimeM_RealTime.Compare
            SC_TimeM_RealTime_Get: operation=TimeM_RealTime.Get
        Ssa_KeyM_RoutineServices_Routine_Certificate_Self_Check
          60 x sync call:
            SC_CertP_Functions_Certificate_Parse: operation=CertP_Functions.Certificate_Parse
            SC_CertP_Functions_Certificate_Verify: operation=CertP_Functions.Certificate_Verify
            SC_Key_BackendCert_KeyElementGet: operation=Key_BackendCert.KeyElementGet
            SC_Key_RootCert_KeyElementGet: operation=Key_RootCert.KeyElementGet
            SC_Key_SignatureRamKey_KeyElementSet: operation=Key_SignatureRamKey.KeyElementSet
            SC_Key_SignatureRamKey_KeySetValid: operation=Key_SignatureRamKey.KeySetValid
            SC_KeyMCertificate_Ssa_TrustModelBackendCert_GetStatus: operation=KeyMCertificate_Ssa_TrustModelBackendCert.GetStatus
            SC_KeyMCertificate_Ssa_TrustModelEcuCert_GetStatus: operation=KeyMCertificate_Ssa_TrustModelEcuCert.GetStatus
            SC_KeyMCertificate_Ssa_TrustModelIntermediateCert_GetStatus: operation=KeyMCertificate_Ssa_TrustModelIntermediateCert.GetStatus
            SC_KeyMCertificate_Ssa_TrustModelRootCert_GetStatus: operation=KeyMCertificate_Ssa_TrustModelRootCert.GetStatus
            SC_SsaCdd_TrustModel_CsrElementSet: operation=SsaCdd_TrustModel.CsrElementSet
            SC_SsaCdd_TrustModel_GetCertificate: operation=SsaCdd_TrustModel.GetCertificate
            SC_SsaCdd_TrustModel_SetCertificate: operation=SsaCdd_TrustModel.SetCertificate
            SC_Key_TrustModelTempPublicKey_KeyElementGet: operation=Key_TrustModelTempPublicKey.KeyElementGet
            SC_Key_TrustModelTempPublicKey_KeyElementSet: operation=Key_TrustModelTempPublicKey.KeyElementSet
            SC_Key_TrustModelTempPublicKey_KeySetValid: operation=Key_TrustModelTempPublicKey.KeySetValid
            SC_CertP_Functions_ParseTime: operation=CertP_Functions.ParseTime
            SC_KeyMCertificateElement_Ssa_TrustModelBackendCert_ext_authKeyId_CertificateElementGet: operation=KeyMCertificateElement_Ssa_TrustModelBackendCert_ext_authKeyId.CertificateElementGet
            SC_KeyMCertificateElement_Ssa_TrustModelBackendCert_ext_basicConstraints_CertificateElementGet: operation=KeyMCertificateElement_Ssa_TrustModelBackendCert_ext_basicConstraints.CertificateElementGet
            SC_KeyMCertificateElement_Ssa_TrustModelBackendCert_ext_subKeyId_CertificateElementGet: operation=KeyMCertificateElement_Ssa_TrustModelBackendCert_ext_subKeyId.CertificateElementGet
            SC_KeyMCertificateElement_Ssa_TrustModelBackendCert_Issuer_CertificateElementGet: operation=KeyMCertificateElement_Ssa_TrustModelBackendCert_Issuer.CertificateElementGet
            SC_KeyMCertificateElement_Ssa_TrustModelBackendCert_SerialNo_CertificateElementGet: operation=KeyMCertificateElement_Ssa_TrustModelBackendCert_SerialNo.CertificateElementGet
            SC_KeyMCertificateElement_Ssa_TrustModelBackendCert_subject_CertificateElementGet: operation=KeyMCertificateElement_Ssa_TrustModelBackendCert_subject.CertificateElementGet
            SC_KeyMCertificateElement_Ssa_TrustModelBackendCert_SubjectPublicKeyInfoKey_CertificateElementGet: operation=KeyMCertificateElement_Ssa_TrustModelBackendCert_SubjectPublicKeyInfoKey.CertificateElementGet
            SC_KeyMCertificateElement_Ssa_TrustModelBackendCert_validityNotAfter_CertificateElementGet: operation=KeyMCertificateElement_Ssa_TrustModelBackendCert_validityNotAfter.CertificateElementGet
            SC_KeyMCertificateElement_Ssa_TrustModelBackendCert_Version_CertificateElementGet: operation=KeyMCertificateElement_Ssa_TrustModelBackendCert_Version.CertificateElementGet
            SC_KeyMCertificateElement_Ssa_TrustModelEcuCert_ext_authKeyId_CertificateElementGet: operation=KeyMCertificateElement_Ssa_TrustModelEcuCert_ext_authKeyId.CertificateElementGet
            SC_KeyMCertificateElement_Ssa_TrustModelEcuCert_ext_specialEcu_CertificateElementGet: operation=KeyMCertificateElement_Ssa_TrustModelEcuCert_ext_specialEcu.CertificateElementGet
            SC_KeyMCertificateElement_Ssa_TrustModelEcuCert_ext_subKeyId_CertificateElementGet: operation=KeyMCertificateElement_Ssa_TrustModelEcuCert_ext_subKeyId.CertificateElementGet
            SC_KeyMCertificateElement_Ssa_TrustModelEcuCert_ext_uniqueECUID_CertificateElementGet: operation=KeyMCertificateElement_Ssa_TrustModelEcuCert_ext_uniqueECUID.CertificateElementGet
            SC_KeyMCertificateElement_Ssa_TrustModelEcuCert_Issuer_CertificateElementGet: operation=KeyMCertificateElement_Ssa_TrustModelEcuCert_Issuer.CertificateElementGet
            SC_KeyMCertificateElement_Ssa_TrustModelEcuCert_SerialNo_CertificateElementGet: operation=KeyMCertificateElement_Ssa_TrustModelEcuCert_SerialNo.CertificateElementGet
            SC_KeyMCertificateElement_Ssa_TrustModelEcuCert_subject_CertificateElementGet: operation=KeyMCertificateElement_Ssa_TrustModelEcuCert_subject.CertificateElementGet
            SC_KeyMCertificateElement_Ssa_TrustModelEcuCert_SubjectPublicKeyInfoKey_CertificateElementGet: operation=KeyMCertificateElement_Ssa_TrustModelEcuCert_SubjectPublicKeyInfoKey.CertificateElementGet
            SC_KeyMCertificateElement_Ssa_TrustModelEcuCert_validityNotAfter_CertificateElementGet: operation=KeyMCertificateElement_Ssa_TrustModelEcuCert_validityNotAfter.CertificateElementGet
            SC_KeyMCertificateElement_Ssa_TrustModelEcuCert_Version_CertificateElementGet: operation=KeyMCertificateElement_Ssa_TrustModelEcuCert_Version.CertificateElementGet
            SC_KeyMCertificateElement_Ssa_TrustModelIntermediateCert_ext_authKeyId_CertificateElementGet: operation=KeyMCertificateElement_Ssa_TrustModelIntermediateCert_ext_authKeyId.CertificateElementGet
            SC_KeyMCertificateElement_Ssa_TrustModelIntermediateCert_ext_basicConstraints_CertificateElementGet: operation=KeyMCertificateElement_Ssa_TrustModelIntermediateCert_ext_basicConstraints.CertificateElementGet
            SC_KeyMCertificateElement_Ssa_TrustModelIntermediateCert_ext_subKeyId_CertificateElementGet: operation=KeyMCertificateElement_Ssa_TrustModelIntermediateCert_ext_subKeyId.CertificateElementGet
            SC_KeyMCertificateElement_Ssa_TrustModelIntermediateCert_Issuer_CertificateElementGet: operation=KeyMCertificateElement_Ssa_TrustModelIntermediateCert_Issuer.CertificateElementGet
            SC_KeyMCertificateElement_Ssa_TrustModelIntermediateCert_SerialNo_CertificateElementGet: operation=KeyMCertificateElement_Ssa_TrustModelIntermediateCert_SerialNo.CertificateElementGet
            SC_KeyMCertificateElement_Ssa_TrustModelIntermediateCert_subject_CertificateElementGet: operation=KeyMCertificateElement_Ssa_TrustModelIntermediateCert_subject.CertificateElementGet
            SC_KeyMCertificateElement_Ssa_TrustModelIntermediateCert_SubjectPublicKeyInfoKey_CertificateElementGet: operation=KeyMCertificateElement_Ssa_TrustModelIntermediateCert_SubjectPublicKeyInfoKey.CertificateElementGet
            SC_KeyMCertificateElement_Ssa_TrustModelIntermediateCert_validityNotAfter_CertificateElementGet: operation=KeyMCertificateElement_Ssa_TrustModelIntermediateCert_validityNotAfter.CertificateElementGet
            SC_KeyMCertificateElement_Ssa_TrustModelIntermediateCert_Version_CertificateElementGet: operation=KeyMCertificateElement_Ssa_TrustModelIntermediateCert_Version.CertificateElementGet
            SC_KeyMCertificateElement_Ssa_TrustModelRootCert_ext_basicConstraints_CertificateElementGet: operation=KeyMCertificateElement_Ssa_TrustModelRootCert_ext_basicConstraints.CertificateElementGet
            SC_KeyMCertificateElement_Ssa_TrustModelRootCert_ext_keyUsage_CertificateElementGet: operation=KeyMCertificateElement_Ssa_TrustModelRootCert_ext_keyUsage.CertificateElementGet
            SC_KeyMCertificateElement_Ssa_TrustModelRootCert_ext_subKeyId_CertificateElementGet: operation=KeyMCertificateElement_Ssa_TrustModelRootCert_ext_subKeyId.CertificateElementGet
            SC_KeyMCertificateElement_Ssa_TrustModelRootCert_Issuer_CertificateElementGet: operation=KeyMCertificateElement_Ssa_TrustModelRootCert_Issuer.CertificateElementGet
            SC_KeyMCertificateElement_Ssa_TrustModelRootCert_SerialNo_CertificateElementGet: operation=KeyMCertificateElement_Ssa_TrustModelRootCert_SerialNo.CertificateElementGet
            SC_KeyMCertificateElement_Ssa_TrustModelRootCert_subject_CertificateElementGet: operation=KeyMCertificateElement_Ssa_TrustModelRootCert_subject.CertificateElementGet
            SC_KeyMCertificateElement_Ssa_TrustModelRootCert_SubjectPublicKeyInfoKey_CertificateElementGet: operation=KeyMCertificateElement_Ssa_TrustModelRootCert_SubjectPublicKeyInfoKey.CertificateElementGet
            SC_KeyMCertificateElement_Ssa_TrustModelRootCert_validityNotAfter_CertificateElementGet: operation=KeyMCertificateElement_Ssa_TrustModelRootCert_validityNotAfter.CertificateElementGet
            SC_KeyMCertificateElement_Ssa_TrustModelRootCert_Version_CertificateElementGet: operation=KeyMCertificateElement_Ssa_TrustModelRootCert_Version.CertificateElementGet
            SC_SecLog_FailedCertVerificationEvent_FailedCertificateVerification: operation=SecLog_FailedCertVerificationEvent.FailedCertificateVerification
            SC_SecLog_SuccessfulCertVerificationEvent_SuccessfulCertificateVerification: operation=SecLog_SuccessfulCertVerificationEvent.SuccessfulCertificateVerification
            SC_SsaCdd_Csm_SignatureGenerate: operation=SsaCdd_Csm.SignatureGenerate
            SC_SsaCdd_Csm_SignatureVerify: operation=SsaCdd_Csm.SignatureVerify
            SC_TimeM_RealTime_Compare: operation=TimeM_RealTime.Compare
            SC_TimeM_RealTime_Get: operation=TimeM_RealTime.Get
        Ssa_KeyM_RoutineServices_Trust_Model_SecOC_ECU_Shared_Secret_Distribution: can-enter-exclusive-area=KeyM_ExclusiveArea  # Configuration Variant(s): Not in VSM.
          55 x sync call:
            SC_CsmJobKeyExchangeCalcSecret_KeyExchangeCalcSecret: operation=CsmJobKeyExchangeCalcSecret.KeyExchangeCalcSecret
            SC_CsmSymAES128Decrypt_Decrypt: operation=CsmSymAES128Decrypt.Decrypt
            SC_Key_AesRamKey_KeyElementSet: operation=Key_AesRamKey.KeyElementSet
            SC_Key_AesRamKey_KeySetValid: operation=Key_AesRamKey.KeySetValid
            SC_Key_SharedSecretKeyExchange_KeyElementGet: operation=Key_SharedSecretKeyExchange.KeyElementGet
            SC_Key_SharedSecretKeyExchange_KeyElementSet: operation=Key_SharedSecretKeyExchange.KeyElementSet
            SC_Key_SharedSecretKeyExchange_KeyExchangeCalcSecret: operation=Key_SharedSecretKeyExchange.KeyExchangeCalcSecret
            SC_Key_SharedSecretKeyExchange_KeySetValid: operation=Key_SharedSecretKeyExchange.KeySetValid
            SC_Key_SignatureRamKey_KeyElementSet: operation=Key_SignatureRamKey.KeyElementSet
            SC_Key_SignatureRamKey_KeySetValid: operation=Key_SignatureRamKey.KeySetValid
            SC_RightsM_DiagnosticChannel_GetDiagnosticUserRole: operation=RightsM_DiagnosticChannel.GetDiagnosticUserRole
            SC_RightsM_EnhancedRights_VerifySubjectKeyIdentifier: operation=RightsM_EnhancedRights.VerifySubjectKeyIdentifier
            SC_RightsM_Nonce_Destroy: operation=RightsM_Nonce.Destroy
            SC_RightsM_Nonce_Get: operation=RightsM_Nonce.Get
            SC_SecLog_SuccessfulDiagServiceExecutionEvent_TrudtModeEcuSharedSecretDistribution_SuccessfulDiagServiceExecution: operation=SecLog_SuccessfulDiagServiceExecutionEvent_TrustModelEcuSharedSecretDistribution.SuccessfulDiagServiceExecution
            SC_TimeM_TimeRawData_Set: operation=TimeM_TimeRawData.Set
            SC_KeyMCertificate_Ssa_TrustModelBackendPeerCert_GetStatus: operation=KeyMCertificate_Ssa_TrustModelBackendPeerCert.GetStatus
            SC_KeyMCertificate_Ssa_TrustModelEcuPeerCert_GetStatus: operation=KeyMCertificate_Ssa_TrustModelEcuPeerCert.GetStatus
            SC_KeyMCertificate_Ssa_TrustModelEcuPeerCert_VerifyCertificate: operation=KeyMCertificate_Ssa_TrustModelEcuPeerCert.VerifyCertificate
            SC_KeyMCertificate_Ssa_TrustModelIntermediatePeerCert_GetStatus: operation=KeyMCertificate_Ssa_TrustModelIntermediatePeerCert.GetStatus
            SC_KeyMCertificateElement_Ssa_TrustModelEcuPeerCert_ext_subKeyId_CertificateElementGet: operation=KeyMCertificateElement_Ssa_TrustModelEcuPeerCert_ext_subKeyId.CertificateElementGet
            SC_SsaCdd_TrustModel_SetCertificate: operation=SsaCdd_TrustModel.SetCertificate
            SC_CertP_Functions_ParseTime: operation=CertP_Functions.ParseTime
            SC_KeyMCertificateElement_Ssa_TrustModelBackendPeerCert_ext_authKeyId_CertificateElementGet: operation=KeyMCertificateElement_Ssa_TrustModelBackendPeerCert_ext_authKeyId.CertificateElementGet
            SC_KeyMCertificateElement_Ssa_TrustModelBackendPeerCert_ext_basicConstraints_CertificateElementGet: operation=KeyMCertificateElement_Ssa_TrustModelBackendPeerCert_ext_basicConstraints.CertificateElementGet
            SC_KeyMCertificateElement_Ssa_TrustModelBackendPeerCert_ext_subKeyId_CertificateElementGet: operation=KeyMCertificateElement_Ssa_TrustModelBackendPeerCert_ext_subKeyId.CertificateElementGet
            SC_KeyMCertificateElement_Ssa_TrustModelBackendPeerCert_SerialNo_CertificateElementGet: operation=KeyMCertificateElement_Ssa_TrustModelBackendPeerCert_SerialNo.CertificateElementGet
            SC_KeyMCertificateElement_Ssa_TrustModelBackendPeerCert_validityNotAfter_CertificateElementGet: operation=KeyMCertificateElement_Ssa_TrustModelBackendPeerCert_validityNotAfter.CertificateElementGet
            SC_KeyMCertificateElement_Ssa_TrustModelBackendPeerCert_Version_CertificateElementGet: operation=KeyMCertificateElement_Ssa_TrustModelBackendPeerCert_Version.CertificateElementGet
            SC_KeyMCertificateElement_Ssa_TrustModelEcuPeerCert_ext_authKeyId_CertificateElementGet: operation=KeyMCertificateElement_Ssa_TrustModelEcuPeerCert_ext_authKeyId.CertificateElementGet
            SC_KeyMCertificateElement_Ssa_TrustModelEcuPeerCert_ext_specialEcu_CertificateElementGet: operation=KeyMCertificateElement_Ssa_TrustModelEcuPeerCert_ext_specialEcu.CertificateElementGet
            SC_KeyMCertificateElement_Ssa_TrustModelEcuPeerCert_SerialNo_CertificateElementGet: operation=KeyMCertificateElement_Ssa_TrustModelEcuPeerCert_SerialNo.CertificateElementGet
            SC_KeyMCertificateElement_Ssa_TrustModelEcuPeerCert_validityNotAfter_CertificateElementGet: operation=KeyMCertificateElement_Ssa_TrustModelEcuPeerCert_validityNotAfter.CertificateElementGet
            SC_KeyMCertificateElement_Ssa_TrustModelEcuPeerCert_Version_CertificateElementGet: operation=KeyMCertificateElement_Ssa_TrustModelEcuPeerCert_Version.CertificateElementGet
            SC_KeyMCertificateElement_Ssa_TrustModelIntermediatePeerCert_ext_authKeyId_CertificateElementGet: operation=KeyMCertificateElement_Ssa_TrustModelIntermediatePeerCert_ext_authKeyId.CertificateElementGet
            SC_KeyMCertificateElement_Ssa_TrustModelIntermediatePeerCert_ext_basicConstraints_CertificateElementGet: operation=KeyMCertificateElement_Ssa_TrustModelIntermediatePeerCert_ext_basicConstraints.CertificateElementGet
            SC_KeyMCertificateElement_Ssa_TrustModelIntermediatePeerCert_ext_subKeyId_CertificateElementGet: operation=KeyMCertificateElement_Ssa_TrustModelIntermediatePeerCert_ext_subKeyId.CertificateElementGet
            SC_KeyMCertificateElement_Ssa_TrustModelIntermediatePeerCert_SerialNo_CertificateElementGet: operation=KeyMCertificateElement_Ssa_TrustModelIntermediatePeerCert_SerialNo.CertificateElementGet
            SC_KeyMCertificateElement_Ssa_TrustModelIntermediatePeerCert_validityNotAfter_CertificateElementGet: operation=KeyMCertificateElement_Ssa_TrustModelIntermediatePeerCert_validityNotAfter.CertificateElementGet
            SC_KeyMCertificateElement_Ssa_TrustModelIntermediatePeerCert_Version_CertificateElementGet: operation=KeyMCertificateElement_Ssa_TrustModelIntermediatePeerCert_Version.CertificateElementGet
            SC_KeyMCertificateElement_Ssa_TrustModelRootCert_ext_basicConstraints_CertificateElementGet: operation=KeyMCertificateElement_Ssa_TrustModelRootCert_ext_basicConstraints.CertificateElementGet
            SC_KeyMCertificateElement_Ssa_TrustModelRootCert_ext_keyUsage_CertificateElementGet: operation=KeyMCertificateElement_Ssa_TrustModelRootCert_ext_keyUsage.CertificateElementGet
            SC_KeyMCertificateElement_Ssa_TrustModelRootCert_ext_subKeyId_CertificateElementGet: operation=KeyMCertificateElement_Ssa_TrustModelRootCert_ext_subKeyId.CertificateElementGet
            SC_KeyMCertificateElement_Ssa_TrustModelRootCert_Issuer_CertificateElementGet: operation=KeyMCertificateElement_Ssa_TrustModelRootCert_Issuer.CertificateElementGet
            SC_KeyMCertificateElement_Ssa_TrustModelRootCert_SerialNo_CertificateElementGet: operation=KeyMCertificateElement_Ssa_TrustModelRootCert_SerialNo.CertificateElementGet
            SC_KeyMCertificateElement_Ssa_TrustModelRootCert_subject_CertificateElementGet: operation=KeyMCertificateElement_Ssa_TrustModelRootCert_subject.CertificateElementGet
            SC_KeyMCertificateElement_Ssa_TrustModelRootCert_SubjectPublicKeyInfoKey_CertificateElementGet: operation=KeyMCertificateElement_Ssa_TrustModelRootCert_SubjectPublicKeyInfoKey.CertificateElementGet
            SC_KeyMCertificateElement_Ssa_TrustModelRootCert_validityNotAfter_CertificateElementGet: operation=KeyMCertificateElement_Ssa_TrustModelRootCert_validityNotAfter.CertificateElementGet
            SC_KeyMCertificateElement_Ssa_TrustModelRootCert_Version_CertificateElementGet: operation=KeyMCertificateElement_Ssa_TrustModelRootCert_Version.CertificateElementGet
            SC_SecLog_FailedCertVerificationEvent_FailedCertificateVerification: operation=SecLog_FailedCertVerificationEvent.FailedCertificateVerification
            SC_SecLog_SuccessfulCertVerificationEvent_SuccessfulCertificateVerification: operation=SecLog_SuccessfulCertVerificationEvent.SuccessfulCertificateVerification
            SC_SsaCdd_Csm_Hash: operation=SsaCdd_Csm.Hash
            SC_SsaCdd_Csm_SignatureGenerate: operation=SsaCdd_Csm.SignatureGenerate
            SC_SsaCdd_Csm_SignatureVerify: operation=SsaCdd_Csm.SignatureVerify
            SC_RightsM_DiagnosticChannel_GetPostProductionStatus: operation=RightsM_DiagnosticChannel.GetPostProductionStatus
        Ssa_KeyM_CsmCallbackNotification_RandomGenerate  # Configuration Variant(s): Asynchronous job processing.
        Ssa_KeyM_CsmCallbackNotification_SignatureVerify_ReplacementAuthority  # Configuration Variant(s): Asynchronous job processing.
        Ssa_KeyM_CsmCallbackNotification_RandomSeed  # Configuration Variant(s): Asynchronous key management job processing. Configuration Variant(s): Not in VSM.
        Ssa_KeyM_CsmCallbackNotification_SignatureGenerate_TrustModelEcuLive  # Configuration Variant(s): Asynchronous job processing.
        Ssa_KeyM_CsmCallbackNotification_SignatureVerify_TrustModelBackend  # Configuration Variant(s): Asynchronous job processing. Configuration Variant(s): Not in VSM.
        Ssa_KeyM_CsmCallbackNotification_SignatureVerify_TrustModelTemp  # Configuration Variant(s): Asynchronous job processing.
        Ssa_KeyM_RoutineServices_Get_Certificate_Entry_Start
          28 x sync call:
            SC_CertP_Functions_AttributeCertificate_Parse: operation=CertP_Functions.AttributeCertificate_Parse
            SC_CertP_Functions_Certificate_Parse: operation=CertP_Functions.Certificate_Parse
            SC_KeyMCertificateElement_Ssa_TrustModelBackendCert_ext_authKeyId_CertificateElementGet: operation=KeyMCertificateElement_Ssa_TrustModelBackendCert_ext_authKeyId.CertificateElementGet
            SC_KeyMCertificateElement_Ssa_TrustModelBackendCert_ext_subKeyId_CertificateElementGet: operation=KeyMCertificateElement_Ssa_TrustModelBackendCert_ext_subKeyId.CertificateElementGet
            SC_KeyMCertificateElement_Ssa_TrustModelBackendCert_Issuer_CertificateElementGet: operation=KeyMCertificateElement_Ssa_TrustModelBackendCert_Issuer.CertificateElementGet
            SC_KeyMCertificateElement_Ssa_TrustModelBackendCert_SerialNo_CertificateElementGet: operation=KeyMCertificateElement_Ssa_TrustModelBackendCert_SerialNo.CertificateElementGet
            SC_KeyMCertificateElement_Ssa_TrustModelBackendCert_subject_CertificateElementGet: operation=KeyMCertificateElement_Ssa_TrustModelBackendCert_subject.CertificateElementGet
            SC_KeyMCertificateElement_Ssa_TrustModelBackendCert_SubjectPublicKeyInfoKey_CertificateElementGet: operation=KeyMCertificateElement_Ssa_TrustModelBackendCert_SubjectPublicKeyInfoKey.CertificateElementGet
            SC_KeyMCertificateElement_Ssa_TrustModelEcuCert_ext_authKeyId_CertificateElementGet: operation=KeyMCertificateElement_Ssa_TrustModelEcuCert_ext_authKeyId.CertificateElementGet
            SC_KeyMCertificateElement_Ssa_TrustModelEcuCert_ext_specialEcu_CertificateElementGet: operation=KeyMCertificateElement_Ssa_TrustModelEcuCert_ext_specialEcu.CertificateElementGet
            SC_KeyMCertificateElement_Ssa_TrustModelEcuCert_ext_subKeyId_CertificateElementGet: operation=KeyMCertificateElement_Ssa_TrustModelEcuCert_ext_subKeyId.CertificateElementGet
            SC_KeyMCertificateElement_Ssa_TrustModelEcuCert_ext_uniqueECUID_CertificateElementGet: operation=KeyMCertificateElement_Ssa_TrustModelEcuCert_ext_uniqueECUID.CertificateElementGet
            SC_KeyMCertificateElement_Ssa_TrustModelEcuCert_Issuer_CertificateElementGet: operation=KeyMCertificateElement_Ssa_TrustModelEcuCert_Issuer.CertificateElementGet
            SC_KeyMCertificateElement_Ssa_TrustModelEcuCert_SerialNo_CertificateElementGet: operation=KeyMCertificateElement_Ssa_TrustModelEcuCert_SerialNo.CertificateElementGet
            SC_KeyMCertificateElement_Ssa_TrustModelEcuCert_subject_CertificateElementGet: operation=KeyMCertificateElement_Ssa_TrustModelEcuCert_subject.CertificateElementGet
            SC_KeyMCertificateElement_Ssa_TrustModelEcuCert_SubjectPublicKeyInfoKey_CertificateElementGet: operation=KeyMCertificateElement_Ssa_TrustModelEcuCert_SubjectPublicKeyInfoKey.CertificateElementGet
            SC_KeyMCertificateElement_Ssa_TrustModelIntermediateCert_ext_authKeyId_CertificateElementGet: operation=KeyMCertificateElement_Ssa_TrustModelIntermediateCert_ext_authKeyId.CertificateElementGet
            SC_KeyMCertificateElement_Ssa_TrustModelIntermediateCert_ext_subKeyId_CertificateElementGet: operation=KeyMCertificateElement_Ssa_TrustModelIntermediateCert_ext_subKeyId.CertificateElementGet
            SC_KeyMCertificateElement_Ssa_TrustModelIntermediateCert_Issuer_CertificateElementGet: operation=KeyMCertificateElement_Ssa_TrustModelIntermediateCert_Issuer.CertificateElementGet
            SC_KeyMCertificateElement_Ssa_TrustModelIntermediateCert_SerialNo_CertificateElementGet: operation=KeyMCertificateElement_Ssa_TrustModelIntermediateCert_SerialNo.CertificateElementGet
            SC_KeyMCertificateElement_Ssa_TrustModelIntermediateCert_subject_CertificateElementGet: operation=KeyMCertificateElement_Ssa_TrustModelIntermediateCert_subject.CertificateElementGet
            SC_KeyMCertificateElement_Ssa_TrustModelIntermediateCert_SubjectPublicKeyInfoKey_CertificateElementGet: operation=KeyMCertificateElement_Ssa_TrustModelIntermediateCert_SubjectPublicKeyInfoKey.CertificateElementGet
            SC_KeyMCertificateElement_Ssa_TrustModelRootCert_ext_keyUsage_CertificateElementGet: operation=KeyMCertificateElement_Ssa_TrustModelRootCert_ext_keyUsage.CertificateElementGet
            SC_KeyMCertificateElement_Ssa_TrustModelRootCert_ext_subKeyId_CertificateElementGet: operation=KeyMCertificateElement_Ssa_TrustModelRootCert_ext_subKeyId.CertificateElementGet
            SC_KeyMCertificateElement_Ssa_TrustModelRootCert_Issuer_CertificateElementGet: operation=KeyMCertificateElement_Ssa_TrustModelRootCert_Issuer.CertificateElementGet
            SC_KeyMCertificateElement_Ssa_TrustModelRootCert_SerialNo_CertificateElementGet: operation=KeyMCertificateElement_Ssa_TrustModelRootCert_SerialNo.CertificateElementGet
            SC_KeyMCertificateElement_Ssa_TrustModelRootCert_subject_CertificateElementGet: operation=KeyMCertificateElement_Ssa_TrustModelRootCert_subject.CertificateElementGet
            SC_KeyMCertificateElement_Ssa_TrustModelRootCert_SubjectPublicKeyInfoKey_CertificateElementGet: operation=KeyMCertificateElement_Ssa_TrustModelRootCert_SubjectPublicKeyInfoKey.CertificateElementGet
        Ssa_KeyM_RoutineServices_Inject_Seed  # Configuration Variant(s): Not in VSM.
          16 x sync call:
            SC_CsmJobKeyExchangeCalcSecret_KeyExchangeCalcSecret: operation=CsmJobKeyExchangeCalcSecret.KeyExchangeCalcSecret
            SC_CsmJobRandomSeed_RandomSeed: operation=CsmJobRandomSeed.RandomSeed
            SC_Key_AesRamKey_KeyElementSet: operation=Key_AesRamKey.KeyElementSet
            SC_Key_AesRamKey_KeySetValid: operation=Key_AesRamKey.KeySetValid
            SC_Key_RandomSeed_KeySetValid: operation=Key_RandomSeed.KeySetValid
            SC_Key_RandomSeed_RandomSeed: operation=Key_RandomSeed.RandomSeed
            SC_Key_SharedSecretKeyExchange_KeyElementGet: operation=Key_SharedSecretKeyExchange.KeyElementGet
            SC_Key_SharedSecretKeyExchange_KeyExchangeCalcSecret: operation=Key_SharedSecretKeyExchange.KeyExchangeCalcSecret
            SC_Key_SharedSecretKeyExchange_KeySetValid: operation=Key_SharedSecretKeyExchange.KeySetValid
            SC_RightsM_Nonce_Destroy: operation=RightsM_Nonce.Destroy
            SC_RightsM_Nonce_Get: operation=RightsM_Nonce.Get
            SC_Ssa_KeyExchange_Prepare: operation=Ssa_KeyProc.PrepareKeyExchange
            SC_Ssa_KeyStorage_StorePermanently: operation=Ssa_KeyStorage.StorePermanently
            SC_CsmSymAES128DecryptWithPadding_Decrypt: operation=CsmSymAES128DecryptWithPadding.Decrypt
            SC_SecLog_SuccessfulDiagServiceExecutionEvent_InjectSeed_SuccessfulDiagServiceExecution: operation=SecLog_SuccessfulDiagServiceExecutionEvent_InjectSeed.SuccessfulDiagServiceExecution
            SC_SsaCdd_Csm_SignatureVerify: operation=SsaCdd_Csm.SignatureVerify
        Ssa_KeyM_RoutineServices_Trust_Model_Generate_Key_Pair
          15 x sync call:
            SC_CsmJobKeyGenerate_TrustModelEcuStaging_KeyGenerate: operation=CsmJobKeyGenerate_TrustModelEcuCsr.KeyGenerate
            SC_Key_TrustModelTempPublicKey_KeyElementSet: operation=Key_TrustModelTempPublicKey.KeyElementSet
            SC_Ssa_KeyProc_GenerateKeyPair: operation=Ssa_KeyProc.GenerateKeyPair
            SC_SsaCdd_TrustModel_CsrElementSet: operation=SsaCdd_TrustModel.CsrElementSet
            SC_SsaCdd_TrustModel_ServiceCertificate: operation=SsaCdd_TrustModel.ServiceCertificate
            SC_Key_TrustModelEcuCsrPrivateKey_KeyElementCopy_1: operation=Key_TrustModelEcuCsrPrivateKey.KeyElementCopy
            SC_Key_TrustModelEcuCsrPrivateKey_KeyGenerate_1: operation=Key_TrustModelEcuCsrPrivateKey.KeyGenerate
            SC_Key_TrustModelEcuCsrPrivateKey_KeySetValid_1: operation=Key_TrustModelEcuCsrPrivateKey.KeySetValid
            SC_Key_TrustModelEcuCsrPublicKey_KeyElementGet_1: operation=Key_TrustModelEcuCsrPublicKey.KeyElementGet
            SC_Key_TrustModelEcuCsrPublicKey_KeySetValid_1: operation=Key_TrustModelEcuCsrPublicKey.KeySetValid
            SC_Key_TrustModelTempPublicKey_KeySetValid: operation=Key_TrustModelTempPublicKey.KeySetValid
            SC_SecLog_SuccessfulDiagServiceExecutionEvent_TrustModelGenerateKeyPair_SuccessfulDiagServiceExecution: operation=SecLog_SuccessfulDiagServiceExecutionEvent_TrustModelGenerateKeyPair.SuccessfulDiagServiceExecution
            SC_Ssa_VedocRelevantInfo_GetData: operation=Ssa_VeDocRelevantInfo.GetData
            SC_SsaCdd_Csm_SignatureGenerate: operation=SsaCdd_Csm.SignatureGenerate
            SC_SsaCdd_Csm_SignatureVerify: operation=SsaCdd_Csm.SignatureVerify
        Ssa_KeyM_Certificate_CheckTrustModelChainOfTrust: can-be-invoked-concurrently=true
        Ssa_KeyM_Certificate_SignData1024ByteWithEcuPrivateKey
          sync call SC_SsaCdd_Csm_SignatureGenerate: operation=SsaCdd_Csm.SignatureGenerate
        Ssa_KeyM_Certificate_SignData4092ByteWithEcuPrivateKey
          sync call SC_SsaCdd_Csm_SignatureGenerate: operation=SsaCdd_Csm.SignatureGenerate
        Ssa_KeyM_CsmCallbackNotification_KeyGenerate_TrustModelEcuCsr  # Configuration Variant(s): Asynchronous key management job processing.
        Ssa_KeyM_CsmCallbackNotification_SignatureGenerate_TrustModelEcuCsr  # Configuration Variant(s): Asynchronous job processing.
        Ssa_KeyM_DataServices_DID_0198_Root_Replacement_Key_ConditionCheckRead
          sync call SC_Key_TrustModelRootReplacementKey_KeyElementGet: operation=Key_TrustModelRootReplacementKey.KeyElementGet
        Ssa_KeyM_DataServices_DID_0198_Root_Replacement_Key_ReadData
          sync call SC_Key_TrustModelRootReplacementKey_KeyElementGet: operation=Key_TrustModelRootReplacementKey.KeyElementGet
        Ssa_KeyM_KeyMCertificateVerifyCallback_TrustModelBackend
        Ssa_KeyM_KeyMCertificateVerifyCallback_TrustModelBackendPeer
        Ssa_KeyM_KeyMCertificateVerifyCallback_TrustModelEcu
        Ssa_KeyM_KeyMCertificateVerifyCallback_TrustModelEcuCsr
        Ssa_KeyM_KeyMCertificateVerifyCallback_TrustModelEcuPeer
        Ssa_KeyM_KeyMCertificateVerifyCallback_TrustModelIntermediate
        Ssa_KeyM_KeyMCertificateVerifyCallback_TrustModelIntermediatePeer
        Ssa_KeyM_KeyMCertificateVerifyCallback_TrustModelRoot
        Ssa_KeyM_KeyMServiceCertificateCallback_TrustModelBackend
        Ssa_KeyM_KeyMServiceCertificateCallback_TrustModelBackendPeer
        Ssa_KeyM_KeyMServiceCertificateCallback_TrustModelEcu
        Ssa_KeyM_KeyMServiceCertificateCallback_TrustModelEcuCsr
        Ssa_KeyM_KeyMServiceCertificateCallback_TrustModelEcuPeer
        Ssa_KeyM_KeyMServiceCertificateCallback_TrustModelIntermediate
        Ssa_KeyM_KeyMServiceCertificateCallback_TrustModelIntermediatePeer
        Ssa_KeyM_KeyMServiceCertificateCallback_TrustModelRoot
      swc service dependency NvM_KeyM_TrustModelChainOfTrustState
        assigned-datas:
          role=ramBlock, used-data-element=KeyMTrustModelChainOfTrustState
          role=defaultValue, used-parameter-element=NvM_KeyM_TrustModelChainOfTrustState_DefaultValue
        service-needs:
          nv block needs NvM_KeyM_TrustModelChainOfTrustState: n-data-sets=0, ram-block-status-control=API, reliability=NO-PROTECTION, restore-at-start=true, store-at-shutdown=false
      shared-parameters:
        parameter data prototype NvM_KeyM_TrustModelChainOfTrustState_DefaultValue: type=Ssa_TrustModelChainState_Type, init-value=SSA_TRUSTMODELCHAINSTATE_INITIAL
  swc implementation Ssa_KeyM_Implementation: behavior=Ssa_KeyM_InternalBehavior
    code-descriptors:
      code Default: artifact-descriptors=autosar-engineering-object=category=SWSRC
